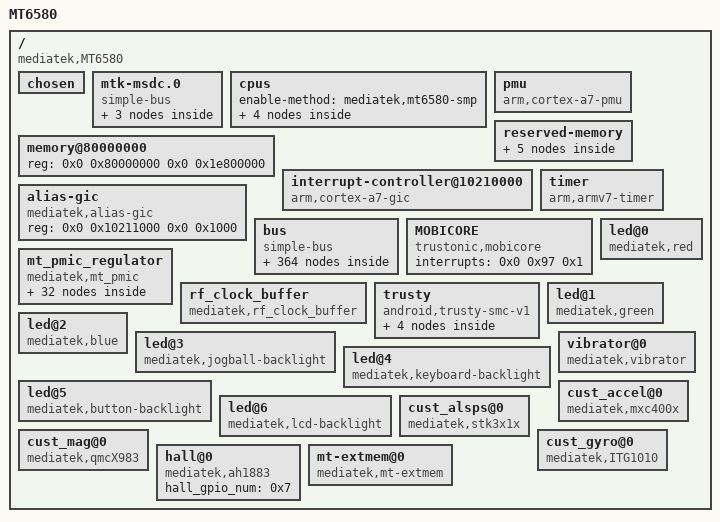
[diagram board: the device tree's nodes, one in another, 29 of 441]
/dts-v1/;

/ {
	model = "MT6580";
	compatible = "mediatek,MT6580";
	interrupt-parent = <0x1>;
	#address-cells = <0x2>;
	#size-cells = <0x2>;

	chosen {
		bootargs = "console=tty0 console=ttyMT0,921600n1 root=/dev/ram initrd=0x84000000,0x400000 loglevel=8";
		atag,videolfb-fb_base = <0x9e800000>;
		atag,videolfb-islcmfound = <0x1>;
		atag,videolfb-fps = <0x1770>;
		atag,videolfb-vramSize = <0x1800000>;
		atag,videolfb-lcmname = "nt35590_AUO";
	};

	mtk-msdc.0 {
		compatible = "simple-bus";
		#address-cells = <0x1>;
		#size-cells = <0x1>;
		ranges = <0x0 0x0 0x0 0xffffffff>;

		msdc0@11120000 {
			compatible = "mediatek,mt6580-mmc";
			reg = <0x11120000 0x10000 0x10001e84 0x2>;
			interrupts = <0x0 0x26 0x8>;
			status = "okay";
			clk_src = [07];
			bus-width = <0x8>;
			max-frequency = <0xc65d400>;
			cap-mmc-highspeed;
			msdc-sys-suspend;
			mmc-hs200-1_8v;
			non-removable;
			pinctl = <0x2>;
			register_setting = <0x3>;
			host_function = [00];
			bootable;
		};

		msdc1@11130000 {
			compatible = "mediatek,mt6580-mmc";
			reg = <0x11130000 0x10000 0x10001e84 0x2>;
			interrupts = <0x0 0x27 0x8>;
			cd-gpios = <0x4 0x14 0x0>;
			status = "okay";
			clk_src = [02];
			bus-width = <0x4>;
			max-frequency = <0xc65d400>;
			msdc-sys-suspend;
			cap-sd-highspeed;
			sd-uhs-sdr12;
			sd-uhs-sdr25;
			sd-uhs-sdr50;
			sd-uhs-sdr104;
			pinctrl-names = "default", "insert_cfg";
			pinctrl-0 = <0x5>;
			pinctrl-1 = <0x6>;
			pinctl = <0x7>;
			pinctl_sdr104 = <0x8>;
			pinctl_sdr50 = <0x9>;
			pinctl_ddr50 = <0xa>;
			register_setting = <0xb>;
			host_function = [01];
			cd_level = [00];
		};

		default {
			compatible = "mediatek,msdc1_ins-eint";
			interrupt-parent = <0xc>;
			interrupts = <0x14 0x8>;
			debounce = <0x14 0x0>;
			status = "okay";
		};
	};

	cpus {
		#address-cells = <0x1>;
		#size-cells = <0x0>;
		enable-method = "mediatek,mt6580-smp";

		cpu@0 {
			device_type = "cpu";
			compatible = "arm,cortex-a7";
			reg = <0x0>;
			clock-frequency = <0x6553f100>;
		};

		cpu@1 {
			device_type = "cpu";
			compatible = "arm,cortex-a7";
			reg = <0x1>;
			clock-frequency = <0x6553f100>;
		};

		cpu@2 {
			device_type = "cpu";
			compatible = "arm,cortex-a7";
			reg = <0x2>;
			clock-frequency = <0x6553f100>;
		};

		cpu@3 {
			device_type = "cpu";
			compatible = "arm,cortex-a7";
			reg = <0x3>;
			clock-frequency = <0x6553f100>;
		};
	};

	pmu {
		compatible = "arm,cortex-a7-pmu";
		interrupts = <0x0 0x4 0x8 0x0 0x5 0x8 0x0 0x6 0x8 0x0 0x7 0x8>;
	};

	memory@80000000 {
		device_type = "memory";
		reg = <0x0 0x80000000 0x0 0x1e800000>;
	};

	reserved-memory {
		#address-cells = <0x2>;
		#size-cells = <0x2>;
		ranges;

		consys-reserve-memory {
			compatible = "mediatek,consys-reserve-memory";
			no-map;
			size = <0x0 0x200000>;
			alignment = <0x0 0x200000>;
		};

		reserve-memory-ccci_md1 {
			compatible = "mediatek,reserve-memory-ccci_md1";
			no-map;
			size = <0x0 0x1800000>;
			alignment = <0x0 0x2000000>;
			alloc-ranges = <0x0 0x80000000 0x0 0x80000000>;
		};

		pstore-reserved-memory@83f10000 {
			compatible = "mediatek,pstore";
			reg = <0x0 0x83f10000 0x0 0xe0000>;
		};

		ram_console-reserved-memory@83f00000 {
			compatible = "mediatek,ram_console";
			reg = <0x0 0x83f00000 0x0 0x10000>;
		};

		minirdump-reserved-memory@83ff0000 {
			compatible = "mediatek, minirdump";
			reg = <0x0 0x83ff0000 0x0 0x10000>;
		};
	};

	interrupt-controller@10210000 {
		compatible = "arm,cortex-a7-gic";
		#interrupt-cells = <0x3>;
		#address-cells = <0x0>;
		interrupt-controller;
		reg = <0x0 0x10211000 0x0 0x1000 0x0 0x10212000 0x0 0x1000 0x0 0x10200100 0x0 0x1000>;
		interrupts = <0x1 0x9 0xf04>;
		linux,phandle = <0x1>;
		phandle = <0x1>;
	};

	alias-gic {
		compatible = "mediatek,alias-gic";
		reg = <0x0 0x10211000 0x0 0x1000>;
	};

	timer {
		compatible = "arm,armv7-timer";
		interrupts = <0x1 0xd 0x8 0x1 0xe 0x8 0x1 0xb 0x8 0x1 0xa 0x8>;
		clock-frequency = <0xc65d40>;
	};

	bus {
		compatible = "simple-bus";
		#address-cells = <0x1>;
		#size-cells = <0x1>;
		ranges = <0x0 0x0 0x0 0xffffffff>;

		chipid@08000000 {
			compatible = "mediatek,chipid";
			reg = <0x8000000 0x4 0x8000004 0x4 0x8000008 0x4 0x800000c 0x4>;
		};

		TOPCKGEN@0x10000000 {
			compatible = "mediatek,TOPCKGEN";
			reg = <0x10000000 0x1000>;
		};

		INFRACFG_AO@0x10001000 {
			compatible = "mediatek,INFRACFG_AO";
			reg = <0x10001000 0x1000>;
		};

		bat_meter {
			compatible = "mediatek,bat_meter";
			r_bat_sense = <0x4>;
			r_i_sense = <0x4>;
			r_charger_1 = <0x14a>;
			r_charger_2 = <0x27>;
			temperature_t0 = <0x6e>;
			temperature_t1 = <0x0>;
			temperature_t2 = <0x19>;
			temperature_t3 = <0x32>;
			temperature_t = <0xff>;
			fg_meter_resistance = <0x0>;
			q_max_pos_50 = <0x1359>;
			q_max_pos_25 = <0x13ec>;
			q_max_pos_0 = <0x13b2>;
			q_max_neg_10 = <0x11e3>;
			q_max_pos_50_h_current = <0x132f>;
			q_max_pos_25_h_current = <0x13ba>;
			q_max_pos_0_h_current = <0x1279>;
			q_max_neg_10_h_current = <0xdd0>;
			oam_d5 = <0x0>;
			change_tracking_point = <0x1>;
			cust_tracking_point = <0x0>;
			cust_r_sense = <0xc8>;
			cust_hw_cc = <0x0>;
			aging_tuning_value = <0x67>;
			cust_r_fg_offset = <0x0>;
			ocv_board_compesate = <0x0>;
			r_fg_board_base = <0x3e8>;
			r_fg_board_slope = <0x3e8>;
			car_tune_value = <0x59>;
			current_detect_r_fg = <0xa>;
			minerroroffset = <0x3e8>;
			fg_vbat_average_size = <0x12>;
			r_fg_value = <0xa>;
			cust_poweron_delta_capacity_tolrance = <0x1e>;
			cust_poweron_low_capacity_tolrance = <0x5>;
			cust_poweron_max_vbat_tolrance = <0x5a>;
			cust_poweron_delta_vbat_tolrance = <0x1e>;
			cust_poweron_delta_hw_sw_ocv_capacity_tolrance = <0xa>;
			fixed_tbat_25 = <0x0>;
			vbat_normal_wakeup = <0xe10>;
			vbat_low_power_wakeup = <0xdac>;
			normal_wakeup_period = <0x1518>;
			low_power_wakeup_period = <0x12c>;
			close_poweroff_wakeup_period = <0x1e>;
			rbat_pull_up_r = <0x4204>;
			rbat_pull_up_volt = <0x708>;
			batt_temperature_table_num = <0x13>;
			batt_temperature_table = <0xffffffec 0x10a8d 0xfffffff1 0xd192 0xfffffff6 0xa60a 0xfffffffb 0x8464 0x0 0x6a53 0x5 0x5605 0xa 0x4606 0xf 0x3952 0x14 0x2f31 0x19 0x2710 0x1e 0x207b 0x23 0x1b24 0x28 0x16ca 0x2d 0x1335 0x32 0x1041 0x37 0xdcf 0x3c 0xbc6 0x41 0xa28 0x46 0x8ca>;
			battery_profile_t0_num = <0x64>;
			battery_profile_t0 = <0x0 0x10e4 0x2 0x10c2 0x4 0x10a8 0x6 0x1091 0x8 0x107c 0x9 0x1068 0xb 0x1054 0xd 0x1041 0xf 0x102e 0x11 0x101b 0x13 0x1009 0x15 0xffa 0x17 0xfed 0x18 0xfd9 0x1a 0xfba 0x1c 0xf9a 0x1e 0xf83 0x20 0xf71 0x22 0xf63 0x24 0xf57 0x26 0xf4b 0x27 0xf3f 0x29 0xf32 0x2b 0xf26 0x2d 0xf1a 0x2f 0xf0f 0x31 0xf04 0x33 0xefb 0x35 0xef2 0x36 0xeeb 0x38 0xee3 0x3a 0xedd 0x3c 0xed7 0x3e 0xed1 0x40 0xecd 0x42 0xeca 0x44 0xec7 0x45 0xec5 0x47 0xec2 0x49 0xebf 0x4b 0xebc 0x4d 0xeb8 0x4f 0xeb4 0x51 0xeaf 0x53 0xea8 0x54 0xea1 0x56 0xe97 0x58 0xe8e 0x5a 0xe83 0x5c 0xe79 0x5e 0xe70 0x60 0xe68 0x61 0xe61 0x62 0xe5a 0x63 0xe50 0x64 0xdc8 0x64 0xdac 0x64 0xdac 0x64 0xdac 0x64 0xdac 0x64 0xdac 0x64 0xdac 0x64 0xdac 0x64 0xdac 0x64 0xdac 0x64 0xdac 0x64 0xdac 0x64 0xdac 0x64 0xdac 0x64 0xdac 0x64 0xdac 0x64 0xdac 0x64 0xdac 0x64 0xdac 0x64 0xdac 0x64 0xdac 0x64 0xdac 0x64 0xdac 0x64 0xdac 0x64 0xdac 0x64 0xdac 0x64 0xdac 0x64 0xdac 0x64 0xdac 0x64 0xdac 0x64 0xdac 0x64 0xdac 0x64 0xdac 0x64 0xdac 0x64 0xdac 0x64 0xdac 0x64 0xdac 0x64 0xdac 0x64 0xdac 0x64 0xdac 0x64 0xdac 0x64 0xdac 0x64 0xdac 0x64 0xdac 0x64 0xdac>;
			battery_profile_t1_num = <0x64>;
			battery_profile_t1 = <0x0 0x10e9 0x2 0x10cd 0x4 0x10b4 0x6 0x10a0 0x7 0x108c 0x9 0x1078 0xb 0x1065 0xd 0x1052 0xf 0x103f 0x11 0x102c 0x12 0x1018 0x14 0x1006 0x16 0xff5 0x18 0xfea 0x1a 0xfdc 0x1c 0xfbc 0x1e 0xf98 0x1f 0xf82 0x21 0xf72 0x23 0xf66 0x25 0xf5b 0x27 0xf4e 0x29 0xf3f 0x2b 0xf31 0x2c 0xf23 0x2e 0xf16 0x30 0xf0b 0x32 0xf01 0x34 0xef8 0x36 0xef0 0x37 0xee8 0x39 0xee2 0x3b 0xedb 0x3d 0xed5 0x3f 0xed0 0x41 0xecb 0x43 0xec7 0x44 0xec3 0x46 0xec0 0x48 0xebe 0x4a 0xeba 0x4c 0xeb7 0x4e 0xeb2 0x4f 0xead 0x51 0xea6 0x53 0xe9e 0x55 0xe93 0x57 0xe89 0x59 0xe7b 0x5b 0xe72 0x5c 0xe6e 0x5e 0xe69 0x60 0xe5c 0x62 0xe28 0x64 0xdbb 0x64 0xdac 0x64 0xdac 0x64 0xdac 0x64 0xdac 0x64 0xdac 0x64 0xdac 0x64 0xdac 0x64 0xdac 0x64 0xdac 0x64 0xdac 0x64 0xdac 0x64 0xdac 0x64 0xdac 0x64 0xdac 0x64 0xdac 0x64 0xdac 0x64 0xdac 0x64 0xdac 0x64 0xdac 0x64 0xdac 0x64 0xdac 0x64 0xdac 0x64 0xdac 0x64 0xdac 0x64 0xdac 0x64 0xdac 0x64 0xdac 0x64 0xdac 0x64 0xdac 0x64 0xdac 0x64 0xdac 0x64 0xdac 0x64 0xdac 0x64 0xdac 0x64 0xdac 0x64 0xdac 0x64 0xdac 0x64 0xdac 0x64 0xdac 0x64 0xdac 0x64 0xdac 0x64 0xdac 0x64 0xdac 0x64 0xdac 0x64 0xdac>;
			battery_profile_t2_num = <0x64>;
			battery_profile_t2 = <0x0 0x10f1 0x2 0x10d8 0x4 0x10c1 0x5 0x10ac 0x7 0x1097 0x9 0x1083 0xb 0x106e 0xd 0x105b 0xf 0x1047 0x10 0x1034 0x12 0x1021 0x14 0x100e 0x16 0xffb 0x18 0xfe9 0x19 0xfde 0x1b 0xfcf 0x1d 0xfb1 0x1f 0xf98 0x21 0xf8b 0x23 0xf84 0x24 0xf79 0x26 0xf6b 0x28 0xf5d 0x2a 0xf4c 0x2c 0xf37 0x2d 0xf24 0x2f 0xf16 0x31 0xf0a 0x33 0xf00 0x35 0xef7 0x37 0xeef 0x38 0xee8 0x3a 0xee1 0x3c 0xeda 0x3e 0xed5 0x40 0xecf 0x41 0xeca 0x43 0xec6 0x45 0xec1 0x47 0xebc 0x49 0xeb5 0x4b 0xead 0x4c 0xea8 0x4e 0xea1 0x50 0xe9b 0x52 0xe96 0x54 0xe8e 0x55 0xe83 0x57 0xe79 0x59 0xe6b 0x5b 0xe64 0x5d 0xe62 0x5f 0xe61 0x60 0xe58 0x62 0xe1b 0x64 0xdac 0x64 0xdac 0x64 0xdac 0x64 0xdac 0x64 0xdac 0x64 0xdac 0x64 0xdac 0x64 0xdac 0x64 0xdac 0x64 0xdac 0x64 0xdac 0x64 0xdac 0x64 0xdac 0x64 0xdac 0x64 0xdac 0x64 0xdac 0x64 0xdac 0x64 0xdac 0x64 0xdac 0x64 0xdac 0x64 0xdac 0x64 0xdac 0x64 0xdac 0x64 0xdac 0x64 0xdac 0x64 0xdac 0x64 0xdac 0x64 0xdac 0x64 0xdac 0x64 0xdac 0x64 0xdac 0x64 0xdac 0x64 0xdac 0x64 0xdac 0x64 0xdac 0x64 0xdac 0x64 0xdac 0x64 0xdac 0x64 0xdac 0x64 0xdac 0x64 0xdac 0x64 0xdac 0x64 0xdac 0x64 0xdac 0x64 0xdac>;
			battery_profile_t3_num = <0x64>;
			battery_profile_t3 = <0x0 0x10d9 0x2 0x10c2 0x4 0x10ad 0x6 0x1098 0x8 0x1083 0x9 0x106f 0xb 0x105a 0xd 0x1046 0xf 0x1033 0x11 0x101f 0x13 0x100c 0x15 0xff9 0x17 0xfe7 0x19 0xfd5 0x1a 0xfc4 0x1c 0xfb3 0x1e 0xfa2 0x20 0xf93 0x22 0xf83 0x24 0xf73 0x26 0xf63 0x28 0xf50 0x29 0xf3c 0x2b 0xf2a 0x2d 0xf1c 0x2f 0xf11 0x31 0xf06 0x33 0xefd 0x35 0xef4 0x37 0xeec 0x39 0xee4 0x3a 0xedd 0x3c 0xed7 0x3e 0xed0 0x40 0xecb 0x42 0xec6 0x44 0xec0 0x46 0xeba 0x48 0xeae 0x4a 0xea4 0x4b 0xe9d 0x4d 0xe95 0x4f 0xe8e 0x51 0xe89 0x53 0xe81 0x55 0xe76 0x57 0xe6c 0x59 0xe5f 0x5b 0xe59 0x5c 0xe58 0x5e 0xe56 0x60 0xe4d 0x62 0xe15 0x64 0xdb2 0x64 0xdac 0x64 0xdac 0x64 0xdac 0x64 0xdac 0x64 0xdac 0x64 0xdac 0x64 0xdac 0x64 0xdac 0x64 0xdac 0x64 0xdac 0x64 0xdac 0x64 0xdac 0x64 0xdac 0x64 0xdac 0x64 0xdac 0x64 0xdac 0x64 0xdac 0x64 0xdac 0x64 0xdac 0x64 0xdac 0x64 0xdac 0x64 0xdac 0x64 0xdac 0x64 0xdac 0x64 0xdac 0x64 0xdac 0x64 0xdac 0x64 0xdac 0x64 0xdac 0x64 0xdac 0x64 0xdac 0x64 0xdac 0x64 0xdac 0x64 0xdac 0x64 0xdac 0x64 0xdac 0x64 0xdac 0x64 0xdac 0x64 0xdac 0x64 0xdac 0x64 0xdac 0x64 0xdac 0x64 0xdac 0x64 0xdac 0x64 0xdac 0x64 0xdac>;
			r_profile_t0_num = <0x64>;
			r_profile_t0 = <0x351 0x10e4 0x351 0x10c2 0x34b 0x10a8 0x344 0x1091 0x334 0x107c 0x32b 0x1068 0x31f 0x1054 0x315 0x1041 0x30c 0x102e 0x301 0x101b 0x2f7 0x1009 0x2f4 0xffa 0x2f5 0xfed 0x2ed 0xfd9 0x2d0 0xfba 0x2b2 0xf9a 0x2a5 0xf83 0x29f 0xf71 0x29c 0xf63 0x29c 0xf57 0x296 0xf4b 0x28d 0xf3f 0x28d 0xf32 0x287 0xf26 0x283 0xf1a 0x27e 0xf0f 0x27e 0xf04 0x27e 0xefb 0x27e 0xef2 0x27e 0xeeb 0x281 0xee3 0x283 0xedd 0x286 0xed7 0x289 0xed1 0x28e 0xecd 0x295 0xeca 0x29f 0xec7 0x2af 0xec5 0x2bb 0xec2 0x2cb 0xebf 0x2da 0xebc 0x2ea 0xeb8 0x303 0xeb4 0x31b 0xeaf 0x337 0xea8 0x352 0xea1 0x379 0xe97 0x3a2 0xe8e 0x3d4 0xe83 0x67 0xe79 0x6e 0xe70 0x77 0xe68 0x78 0xe61 0x76 0xe5a 0x74 0xe50 0x335 0xdc8 0x335 0xdac 0x335 0xdac 0x335 0xdac 0x335 0xdac 0x335 0xdac 0x335 0xdac 0x335 0xdac 0x335 0xdac 0x335 0xdac 0x335 0xdac 0x335 0xdac 0x335 0xdac 0x335 0xdac 0x335 0xdac 0x335 0xdac 0x335 0xdac 0x335 0xdac 0x335 0xdac 0x335 0xdac 0x335 0xdac 0x335 0xdac 0x335 0xdac 0x335 0xdac 0x335 0xdac 0x335 0xdac 0x335 0xdac 0x335 0xdac 0x335 0xdac 0x335 0xdac 0x335 0xdac 0x335 0xdac 0x335 0xdac 0x335 0xdac 0x335 0xdac 0x335 0xdac 0x335 0xdac 0x335 0xdac 0x335 0xdac 0x335 0xdac 0x335 0xdac 0x335 0xdac 0x335 0xdac 0x335 0xdac 0x335 0xdac>;
			r_profile_t1_num = <0x64>;
			r_profile_t1 = <0x198 0x10e9 0x198 0x10cd 0x193 0x10b4 0x18d 0x10a0 0x186 0x108c 0x17e 0x1078 0x178 0x1065 0x173 0x1052 0x170 0x103f 0x16d 0x102c 0x169 0x1018 0x167 0x1006 0x166 0xff5 0x16d 0xfea 0x173 0xfdc 0x164 0xfbc 0x153 0xf98 0x14d 0xf82 0x149 0xf72 0x148 0xf66 0x147 0xf5b 0x13f 0xf4e 0x138 0xf3f 0x130 0xf31 0x12b 0xf23 0x128 0xf16 0x127 0xf0b 0x125 0xf01 0x126 0xef8 0x127 0xef0 0x128 0xee8 0x129 0xee2 0x12b 0xedb 0x12d 0xed5 0x12e 0xed0 0x130 0xecb 0x133 0xec7 0x137 0xec3 0x139 0xec0 0x138 0xebe 0x13c 0xeba 0x140 0xeb7 0x147 0xeb2 0x14c 0xead 0x154 0xea6 0x15c 0xe9e 0x166 0xe93 0x176 0xe89 0x188 0xe7b 0x19c 0xe72 0x1ba 0xe6e 0x1e6 0xe69 0x227 0xe5c 0x264 0xe28 0x2d7 0xdbb 0x2d7 0xdac 0x2d7 0xdac 0x2d7 0xdac 0x2d7 0xdac 0x2d7 0xdac 0x2d7 0xdac 0x2d7 0xdac 0x2d7 0xdac 0x2d7 0xdac 0x2d7 0xdac 0x2d7 0xdac 0x2d7 0xdac 0x2d7 0xdac 0x2d7 0xdac 0x2d7 0xdac 0x2d7 0xdac 0x2d7 0xdac 0x2d7 0xdac 0x2d7 0xdac 0x2d7 0xdac 0x2d7 0xdac 0x2d7 0xdac 0x2d7 0xdac 0x2d7 0xdac 0x2d7 0xdac 0x2d7 0xdac 0x2d7 0xdac 0x2d7 0xdac 0x2d7 0xdac 0x2d7 0xdac 0x2d7 0xdac 0x2d7 0xdac 0x2d7 0xdac 0x2d7 0xdac 0x2d7 0xdac 0x2d7 0xdac 0x2d7 0xdac 0x2d7 0xdac 0x2d7 0xdac 0x2d7 0xdac 0x2d7 0xdac 0x2d7 0xdac 0x2d7 0xdac 0x2d7 0xdac 0x2d7 0xdac>;
			r_profile_t2_num = <0x64>;
			r_profile_t2 = <0x7c 0x10f1 0x7c 0x10d8 0x7d 0x10c1 0x7b 0x10ac 0x7a 0x1097 0x7a 0x1083 0x7a 0x106e 0x7a 0x105b 0x79 0x1047 0x7b 0x1034 0x7d 0x1021 0x7c 0x100e 0x7c 0xffb 0x7c 0xfe9 0x85 0xfde 0x84 0xfcf 0x7d 0xfb1 0x7e 0xf98 0x80 0xf8b 0x88 0xf84 0x89 0xf79 0x8b 0xf6b 0x8d 0xf5d 0x8a 0xf4c 0x81 0xf37 0x7a 0xf24 0x77 0xf16 0x75 0xf0a 0x74 0xf00 0x74 0xef7 0x74 0xeef 0x75 0xee8 0x74 0xee1 0x73 0xeda 0x74 0xed5 0x74 0xecf 0x75 0xeca 0x76 0xec6 0x77 0xec1 0x77 0xebc 0x74 0xeb5 0x71 0xead 0x74 0xea8 0x74 0xea1 0x74 0xe9b 0x77 0xe96 0x76 0xe8e 0x76 0xe83 0x77 0xe79 0x77 0xe6b 0x74 0xe64 0x78 0xe62 0x81 0xe61 0x8c 0xe58 0x87 0xe1b 0x91 0xdac 0x91 0xdac 0x91 0xdac 0x91 0xdac 0x91 0xdac 0x91 0xdac 0x91 0xdac 0x91 0xdac 0x91 0xdac 0x91 0xdac 0x91 0xdac 0x91 0xdac 0x91 0xdac 0x91 0xdac 0x91 0xdac 0x91 0xdac 0x91 0xdac 0x91 0xdac 0x91 0xdac 0x91 0xdac 0x91 0xdac 0x91 0xdac 0x91 0xdac 0x91 0xdac 0x91 0xdac 0x91 0xdac 0x91 0xdac 0x91 0xdac 0x91 0xdac 0x91 0xdac 0x91 0xdac 0x91 0xdac 0x91 0xdac 0x91 0xdac 0x91 0xdac 0x91 0xdac 0x91 0xdac 0x91 0xdac 0x91 0xdac 0x91 0xdac 0x91 0xdac 0x91 0xdac 0x91 0xdac 0x91 0xdac 0x91 0xdac>;
			r_profile_t3_num = <0x64>;
			r_profile_t3 = <0x66 0x10d9 0x66 0x10c2 0x66 0x10ad 0x67 0x1098 0x67 0x1083 0x67 0x106f 0x66 0x105a 0x67 0x1046 0x67 0x1033 0x68 0x101f 0x68 0x100c 0x68 0xff9 0x69 0xfe7 0x6a 0xfd5 0x6c 0xfc4 0x6c 0xfb3 0x6d 0xfa2 0x70 0xf93 0x71 0xf83 0x73 0xf73 0x76 0xf63 0x74 0xf50 0x6d 0xf3c 0x69 0xf2a 0x67 0xf1c 0x68 0xf11 0x67 0xf06 0x67 0xefd 0x67 0xef4 0x66 0xeec 0x67 0xee4 0x68 0xedd 0x68 0xed7 0x69 0xed0 0x6a 0xecb 0x6c 0xec6 0x6d 0xec0 0x6d 0xeba 0x67 0xeae 0x68 0xea4 0x69 0xe9d 0x68 0xe95 0x67 0xe8e 0x6a 0xe89 0x6b 0xe81 0x69 0xe76 0x6b 0xe6c 0x67 0xe5f 0x66 0xe59 0x6d 0xe58 0x76 0xe56 0x7e 0xe4d 0x72 0xe15 0x77 0xdb2 0x89 0xdac 0x89 0xdac 0x89 0xdac 0x89 0xdac 0x89 0xdac 0x89 0xdac 0x89 0xdac 0x89 0xdac 0x89 0xdac 0x89 0xdac 0x89 0xdac 0x89 0xdac 0x89 0xdac 0x89 0xdac 0x89 0xdac 0x89 0xdac 0x89 0xdac 0x89 0xdac 0x89 0xdac 0x89 0xdac 0x89 0xdac 0x89 0xdac 0x89 0xdac 0x89 0xdac 0x89 0xdac 0x89 0xdac 0x89 0xdac 0x89 0xdac 0x89 0xdac 0x89 0xdac 0x89 0xdac 0x89 0xdac 0x89 0xdac 0x89 0xdac 0x89 0xdac 0x89 0xdac 0x89 0xdac 0x89 0xdac 0x89 0xdac 0x89 0xdac 0x89 0xdac 0x89 0xdac 0x89 0xdac 0x89 0xdac 0x89 0xdac 0x89 0xdac>;
		};

		bat_notify {
			compatible = "mediatek,bat_notify";
		};

		bat_comm {
			compatible = "mediatek,battery";
			stop_charging_in_takling = <0x1>;
			talking_recharge_voltage = <0xed8>;
			talking_sync_time = <0x3c>;
			mtk_temperature_recharge_support = <0x1>;
			max_charge_temperature = <0x46>;
			max_charge_temperature_minus_x_degree = <0x41>;
			min_charge_temperature = <0x0>;
			min_charge_temperature_plus_x_degree = <0x6>;
			err_charge_temperature = <0xff>;
			v_pre2cc_thres = <0xd48>;
			v_cc2topoff_thres = <0x1040>;
			recharging_voltage = <0x107c>;
			charging_full_current = <0x64>;
			config_usb_if = <0x0>;
			usb_charger_current_suspend = <0x0>;
			usb_charger_current_unconfigured = <0x1b58>;
			usb_charger_current_configured = <0xc350>;
			usb_charger_current = <0xc350>;
			ac_charger_current = <0x186a0>;
			non_std_ac_charger_current = <0x186a0>;
			charging_host_charger_current = <0xfde8>;
			apple_0_5a_charger_current = <0xc350>;
			apple_1_0a_charger_current = <0xfde8>;
			apple_2_1a_charger_current = <0x13880>;
			bat_low_temp_protect_enable = <0x0>;
			v_charger_enable = <0x0>;
			v_charger_max = <0x1964>;
			v_charger_min = <0x1130>;
			onehundred_percent_tracking_time = <0xa>;
			npercent_tracking_time = <0x14>;
			sync_to_real_tracking_time = <0x3c>;
			v_0percent_tracking = <0xdde>;
			high_battery_voltage_support = <0x1>;
		};

		keypad@10002000 {
			compatible = "mediatek,mt6580-keypad";
			reg = <0x10002000 0x1000>;
			interrupts = <0x0 0x6d 0x2>;
			mediatek,kpd-key-debounce = <0x400>;
			mediatek,kpd-sw-pwrkey = <0x74>;
			mediatek,kpd-hw-pwrkey = <0x8>;
			mediatek,kpd-sw-rstkey = <0x73>;
			mediatek,kpd-hw-rstkey = <0x11>;
			mediatek,kpd-use-extend-type = <0x0>;
			mediatek,kpd-hw-map-num = <0x48>;
			mediatek,kpd-hw-init-map = <0x72 0x0 0x0 0x0 0x0 0x0 0x0 0x0 0x0 0x0 0x66 0x0 0x0 0x0 0x0 0x0 0x0 0x0 0x0 0x0 0x0 0x0 0x0 0x0 0x0 0x0 0x0 0x0 0x0 0x0 0x0 0x0 0x0 0x0 0x0 0x0 0x0 0x0 0x0 0x0 0x0 0x0 0x0 0x0 0x0 0x0 0x0 0x0 0x0 0x0 0x0 0x0 0x0 0x0 0x0 0x0 0x0 0x0 0x0 0x0 0x0 0x0 0x0 0x0 0x0 0x0 0x0 0x0 0x0 0x0 0x0 0x0>;
			mediatek,kpd-pwrkey-eint-gpio = <0x0>;
			mediatek,kpd-pwkey-gpio-din = <0x0>;
			mediatek,kpd-hw-dl-key0 = <0x11>;
			mediatek,kpd-hw-dl-key1 = <0x0>;
			mediatek,kpd-hw-dl-key2 = <0x8>;
			mediatek,kpd-hw-recovery-key = <0x11>;
			mediatek,kpd-hw-factory-key = <0x0>;
			status = "okay";
		};

		PERICFG@0x10003000 {
			compatible = "mediatek,PERICFG";
			reg = <0x10003000 0x1000>;
		};

		RESERVED@0x10004000 {
			compatible = "mediatek,RESERVED";
			reg = <0x10004000 0x1000>;
		};

		gpio {
			compatible = "mediatek,gpio_usage_mapping";
			GPIO_SIM1_HOT_PLUG = <0x9>;
			GPIO_SIM1_SCLK = <0x16>;
			GPIO_SIM1_SIO = <0x17>;
			GPIO_SIM2_SIO = <0x18>;
			GPIO_SIM2_SCLK = <0x19>;
		};

		gpio@0x10005000 {
			compatible = "mediatek,gpio";
			reg = <0x10005000 0x1000>;
		};

		SLEEP@0x10006000 {
			compatible = "mediatek,SLEEP";
			reg = <0x10006000 0x1000>;
			interrupts = <0x0 0x58 0x8 0x0 0x59 0x8 0x0 0x5a 0x8 0x0 0x5b 0x8>;
		};

		TOPRGU@0x10007000 {
			compatible = "mediatek,TOPRGU";
			reg = <0x10007000 0x1000>;
			interrupts = <0x0 0x9d 0x2>;
		};

		APXGPT@0x10008000 {
			compatible = "mediatek,APXGPT";
			reg = <0x10008000 0x1000>;
			interrupts = <0x0 0x5c 0x8>;
			clock-frequency = <0xc65d40>;
		};

		EFUSEC@0x10009000 {
			compatible = "mediatek,EFUSEC";
			reg = <0x10009000 0x1000>;
		};

		hacc@0x1000A000 {
			compatible = "mediatek,hacc";
			reg = <0x1000a000 0x1000>;
			interrupts = <0x0 0x6e 0x0>;
		};

		cpu_dbgapb@10170000 {
			compatible = "mediatek,hw_dbg";
			num = <0x4>;
			reg = <0x10170000 0x2000 0x10172000 0x2000 0x10174000 0x2000 0x10176000 0x2000>;
		};

		eintc@1000b000 {
			compatible = "mediatek,mt-eic";
			reg = <0x1000b000 0x1000>;
			interrupts = <0x0 0x5e 0x4>;
			#interrupt-cells = <0x2>;
			interrupt-controller;
			mediatek,max_eint_num = <0x1a>;
			mediatek,mapping_table_entry = <0x53>;
			mediatek,mapping_table = <0x0 0x0 0x1 0x1 0x2 0x2 0x3 0x3 0x4 0x4 0x5 0x5 0x6 0x6 0x7 0x7 0x8 0x8 0x9 0x9 0xa 0xa 0xb 0xb 0xc 0xc 0xd 0xd 0xe 0xe 0xf 0xf 0x10 0x0 0x11 0x1 0x12 0x2 0x13 0x3 0x14 0x4 0x15 0x5 0x16 0x6 0x17 0x7 0x18 0x8 0x19 0x9 0x1a 0xa 0x1b 0xb 0x1c 0xc 0x1d 0xd 0x1e 0xe 0x1f 0xf 0x20 0x0 0x21 0x1 0x22 0x2 0x23 0x3 0x24 0x4 0x25 0x5 0x26 0x6 0x27 0x7 0x28 0x8 0x29 0x9 0x2a 0xa 0x2b 0xb 0x2c 0xc 0x2d 0xd 0x2e 0xe 0x2f 0xf 0x30 0x0 0x31 0x1 0x32 0x2 0x33 0x3 0x34 0x3 0x35 0x4 0x36 0x5 0x37 0x6 0x38 0x7 0x39 0x8 0x3a 0xa 0x3b 0xb 0x3c 0xc 0x3d 0xd 0x3e 0xe 0x3f 0xf 0x40 0x0 0x41 0x1 0x42 0x2 0x43 0x3 0x44 0x10 0x45 0x4 0x46 0x5 0x47 0x6 0x48 0x7 0x49 0x8 0x4a 0x9 0x4b 0xa 0x4c 0xb 0x4d 0xc 0x4e 0xd 0x51 0x0 0x52 0x1 0x53 0x2 0x54 0x3>;
			mediatek,builtin_entry = <0xb>;
			mediatek,builtin_mapping = <0x0 0x3 0x14 0x1 0x3 0x12 0x7 0x4 0x14 0x8 0x4 0x12 0x9 0x3 0x14 0xa 0x3 0x12 0x18 0x5 0x14 0x19 0x5 0x12 0x4d 0x2 0x14 0x4e 0x2 0x12 0xd 0x1 0x11>;
			linux,phandle = <0xc>;
			phandle = <0xc>;

			MD1_SIM1_HOT_PLUG_EINT@0 {
				compatible = "mediatek,MD1_SIM1_HOT_PLUG_EINT-eint";
				interrupts = <0x0 0x4>;
				debounce = <0x0 0x2710>;
				dedicated = <0x0 0x1>;
				src_pin = <0x0 0x820c078>;
				sockettype = <0x0 0x0>;
				status = "okay";
			};

			pmic@13 {
				compatible = "mediatek, pmic-eint";
				interrupt-parent = <0xc>;
				interrupts = <0xd 0x4>;
				debounce = <0xd 0x3e8>;
			};
		};

		ap_ccif0@1000C000 {
			compatible = "mediatek,ap_ccif0";
			reg = <0x1000c000 0x1000 0x1000d000 0x1000>;
			interrupts = <0x0 0x5d 0x8 0x0 0x98 0x2>;
			mediatek,ccif_capability = <0x2>;
			mediatek,md_smem_size = <0x200000>;
		};

		MCUSYS_CFGREG@0x1020000 {
			compatible = "mediatek,MCUSYS_CFGREG_BASE";
			reg = <0x1020000 0x200>;
		};

		mcucfg@10200000 {
			compatible = "mediatek,mt6580-mcucfg";
			reg = <0x10200000 0x200>;
		};

		AES@0x1000E000 {
			compatible = "mediatek,AES";
			reg = <0x1000e000 0x1000>;
		};

		PWRAP@0x1000F000 {
			compatible = "mediatek,PWRAP";
			reg = <0x1000f000 0x1000>;
			interrupts = <0x0 0x6c 0x0>;
		};

		DEVAPC_AO@0x10010000 {
			compatible = "mediatek,DEVAPC_AO";
			reg = <0x10010000 0x1000>;
		};

		MIPI_CONFG@0x10011000 {
			compatible = "mediatek,MIPI_CONFG";
			reg = <0x10011000 0x1000>;
		};

		INFRA_MBIST@0x10012000 {
			compatible = "mediatek,INFRA_MBIST";
			reg = <0x10012000 0x1000>;
		};

		RESERVED@0x10013000 {
			compatible = "mediatek,RESERVED";
			reg = <0x10013000 0x1000>;
		};

		IOCFG_T@0x10014000 {
			compatible = "mediatek,IOCFG_T";
			reg = <0x10014000 0x1000>;
		};

		IOCFG_B@0x10015000 {
			compatible = "mediatek,IOCFG_B";
			reg = <0x10015000 0x1000>;
		};

		IOCFG_L@0x10016000 {
			compatible = "mediatek,IOCFG_L";
			reg = <0x10016000 0x1000>;
		};

		IOCFG_R@0x10017000 {
			compatible = "mediatek,IOCFG_R";
			reg = <0x10017000 0x1000>;
		};

		APMIXED@0x10018000 {
			compatible = "mediatek,APMIXED";
			reg = <0x10018000 0x1000>;
		};

		MCUCFG@0x10200000 {
			compatible = "mediatek,MCUCFG";
			reg = <0x10200000 0x1000>;
		};

		INFRACFG@0x10201000 {
			compatible = "mediatek,INFRACFG";
			reg = <0x10201000 0x1000>;
		};

		sys_cirq@10202000 {
			compatible = "mediatek,mt6580-sys_cirq", "mediatek,mt6735-sys_cirq";
			reg = <0x10202000 0x1000>;
			interrupts = <0x0 0x9e 0x8>;
			mediatek,cirq_num = <0x7e>;
			mediatek,spi_start_offset = <0x20>;
		};

		m4u@10203000 {
			cell-index = <0x0>;
			compatible = "mediatek,m4u";
			reg = <0x10203000 0x1000>;
			interrupts = <0x0 0x51 0x8>;
		};

		DEVAPC@0x10204000 {
			compatible = "mediatek,DEVAPC";
			reg = <0x10204000 0x1000>;
			interrupts = <0x0 0x4a 0x8>;
		};

		EMI@0x10205000 {
			compatible = "mediatek,EMI";
			reg = <0x10205000 0x1000>;
			interrupts = <0x0 0x4c 0x4>;
		};

		DRAMC_NAO@0x10206000 {
			compatible = "mediatek,DRAMC_NAO";
			reg = <0x10206000 0x1000>;
		};

		DRAMC0@0x10207000 {
			compatible = "mediatek,DRAMC0";
			reg = <0x10207000 0x1000>;
		};

		DDRPHY@0x10208000 {
			compatible = "mediatek,DDRPHY";
			reg = <0x10208000 0x1000>;
		};

		SRAMROM@0x10209000 {
			compatible = "mediatek,SRAMROM";
			reg = <0x10209000 0x1000>;
		};

		gce@1020a000 {
			compatible = "mediatek,gce";
			reg = <0x1020a000 0x1000>;
			interrupts = <0x0 0x55 0x8 0x0 0x56 0x8>;
			disp_mutex_reg = <0x14015000 0x1000>;
			g3d_config_base = <0x13000000 0x0 0xffff0000>;
			mmsys_config_base = <0x14000000 0x1 0xffff0000>;
			disp_dither_base = <0x14010000 0x2 0xffff0000>;
			mm_na_base = <0x14020000 0x3 0xffff0000>;
			imgsys_base = <0x15000000 0x4 0xffff0000>;
			vdec_gcon_base = <0x16000000 0x5 0xffff0000>;
			venc_gcon_base = <0x17000000 0x6 0xffff0000>;
			conn_peri_base = <0x18000000 0x7 0xffff0000>;
			topckgen_base = <0x10000000 0x8 0xffff0000>;
			kp_base = <0x10010000 0x9 0xffff0000>;
			scp_sram_base = <0x10020000 0xa 0xffff0000>;
			infra_na3_base = <0x10030000 0xb 0xffff0000>;
			infra_na4_base = <0x10040000 0xc 0xffff0000>;
			scp_base = <0x10050000 0xd 0xffff0000>;
			mcucfg_base = <0x10200000 0xe 0xffff0000>;
			gcpu_base = <0x10210000 0xf 0xffff0000>;
			usb0_base = <0x11200000 0x10 0xffff0000>;
			usb_sif_base = <0x11210000 0x11 0xffff0000>;
			audio_base = <0x11220000 0x12 0xffff0000>;
			msdc0_base = <0x11230000 0x13 0xffff0000>;
			msdc1_base = <0x11240000 0x14 0xffff0000>;
			msdc2_base = <0x11250000 0x15 0xffff0000>;
			msdc3_base = <0x11260000 0x16 0xffff0000>;
			pwm_sw_base = <0x1100f000 0x63 0xfffff000>;
			mdp_rdma0_sof = <0x0>;
			mdp_rsz0_sof = <0x1>;
			mdp_rsz1_sof = <0x2>;
			mdp_tdshp_sof = <0x3>;
			mdp_wdma_sof = <0x4>;
			mdp_wrot_sof = <0x5>;
			disp_ovl0_sof = <0x6>;
			disp_rdma0_sof = <0x8>;
			disp_wdma0_sof = <0xa>;
			disp_color_sof = <0xc>;
			disp_aal_sof = <0xd>;
			disp_gamma_sof = <0xe>;
			disp_dither_sof = <0xf>;
			disp_pwm0_sof = <0x11>;
			mdp_rdma0_frame_done = <0x12>;
			mdp_rsz0_frame_done = <0x13>;
			mdp_rsz1_frame_done = <0x14>;
			mdp_tdshp_frame_done = <0x15>;
			mdp_wdma_frame_done = <0x16>;
			mdp_wrot_write_frame_done = <0x17>;
			mdp_wrot_read_frame_done = <0x18>;
			disp_ovl0_frame_done = <0x19>;
			disp_rdma0_frame_done = <0x1b>;
			disp_wdma0_frame_done = <0x1d>;
			disp_color_frame_done = <0x1f>;
			disp_aal_frame_done = <0x20>;
			disp_gamma_frame_done = <0x21>;
			disp_dither_frame_done = <0x22>;
			disp_dsi0_frame_done = <0x25>;
			stream_done_0 = <0x26>;
			stream_done_1 = <0x27>;
			stream_done_2 = <0x28>;
			stream_done_3 = <0x29>;
			stream_done_4 = <0x2a>;
			stream_done_5 = <0x2b>;
			stream_done_6 = <0x2c>;
			stream_done_7 = <0x2d>;
			stream_done_8 = <0x2e>;
			stream_done_9 = <0x2f>;
			buf_underrun_event_0 = <0x30>;
			dsi0_te_event = <0x32>;
			isp_frame_done_p2_1 = <0x42>;
			isp_frame_done_p2_0 = <0x43>;
			seninf_cam0_fifo_full = <0x49>;
			apxgpt2_count = <0x10008028>;
		};

		bus_dbg@1020b000 {
			compatible = "mediatek,bus_dbg-v2";
			reg = <0x1020b000 0x1000>;
			interrupts = <0x0 0x49 0x8>;
			two_stage_timeout = <0x1>;
		};

		TRNG@0x1020C000 {
			compatible = "mediatek,TRNG";
			reg = <0x1020c000 0x1000>;
			interrupts = <0x0 0x57 0x8>;
		};

		MCUCFG_BIU@0x1020D000 {
			compatible = "mediatek,MCUCFG_BIU";
			reg = <0x1020d000 0x1000>;
		};

		DBGSYS_DEM@0x1011A000 {
			compatible = "mediatek,DBGSYS_DEM";
			reg = <0x1011a000 0x1000>;
		};

		DBGSYS_CTI@0x10112000 {
			compatible = "mediatek,DBGSYS_CTI";
			reg = <0x10112000 0x1000>;
		};

		DBGSYS_DAPROM@0x10110000 {
			compatible = "mediatek,DBGSYS_DAPROM";
			reg = <0x10110000 0x1000>;
		};

		DBGSYS_CPU@0x10160000 {
			compatible = "mediatek,DBGSYS_CPU";
			reg = <0x10160000 0x20000>;
		};

		DBGSYS_MDSYS@0x10120000 {
			compatible = "mediatek,DBGSYS_MDSYS";
			reg = <0x10120000 0x10000>;
		};

		dma@0x11000000 {
			compatible = "mediatek,ap_dma";
			reg = <0x11000000 0x1000>;
			interrupts = <0x0 0x30 0x8>;
		};

		NFI@0x11001000 {
			compatible = "mediatek,NFI";
			reg = <0x11001000 0x1000>;
			interrupts = <0x0 0x2f 0x8>;
		};

		NFIECC@0x11002000 {
			compatible = "mediatek,NFIECC";
			reg = <0x11002000 0x1000>;
			interrupts = <0x0 0x2e 0x8>;
		};

		adc_hw@11003000 {
			compatible = "mediatek,mt6735-auxadc";
			reg = <0x11003000 0x1000>;
			interrupts = <0x0 0x23 0x2>;

			adc_channel@ {
				compatible = "mediatek,adc_channel";
				mediatek,temperature0 = <0x0>;
				mediatek,temperature1 = <0x1>;
				status = "okay";
			};
		};

		FHCTL@0x11004000 {
			compatible = "mediatek,FHCTL";
			reg = <0x11004000 0x1000>;
		};

		AP_UART0@0x11005000 {
			cell-index = <0x0>;
			compatible = "mediatek,AP_UART0";
			reg = <0x11005000 0x1000>;
			interrupts = <0x0 0x2c 0x8>;
		};

		AP_UART1@0x11006000 {
			cell-index = <0x1>;
			compatible = "mediatek,AP_UART1";
			reg = <0x11006000 0x1000>;
			interrupts = <0x0 0x2d 0x8>;
		};

		AP_DMA_UART0_TX@0x11000480 {
			compatible = "mediatek,AP_DMA_UART0_TX";
			reg = <0x11000480 0x80>;
			interrupts = <0x0 0x38 0x8>;
		};

		AP_DMA_UART0_RX@0x11000500 {
			compatible = "mediatek,AP_DMA_UART0_RX";
			reg = <0x11000500 0x80>;
			interrupts = <0x0 0x39 0x8>;
		};

		AP_DMA_UART1_TX@0x11000580 {
			compatible = "mediatek,AP_DMA_UART1_TX";
			reg = <0x11000580 0x80>;
			interrupts = <0x0 0x3a 0x8>;
		};

		AP_DMA_UART1_RX@0x11000600 {
			compatible = "mediatek,AP_DMA_UART1_RX";
			reg = <0x11000600 0x80>;
			interrupts = <0x0 0x3b 0x8>;
		};

		PWM@0x11008000 {
			compatible = "mediatek,PWM";
			reg = <0x11008000 0x1000>;
			interrupts = <0x0 0x24 0x8>;
		};

		syscfg_pctl_a@0x10005000 {
			compatible = "mediatek,mt6580-pctl-a-syscfg", "syscon";
			reg = <0x10211000 0x1000>;
			linux,phandle = <0xd>;
			phandle = <0xd>;
		};

		pinctrl@0x10005000 {
			compatible = "mediatek,mt6580-pinctrl";
			reg = <0x10005000 0x1000>;
			mediatek,pctl-regmap = <0xd>;
			pins-are-numbered;
			gpio-controller;
			#gpio-cells = <0x2>;
			linux,phandle = <0x4>;
			phandle = <0x4>;

			mmc0@default {
				linux,phandle = <0x2>;
				phandle = <0x2>;

				pins_cmd {
					drive-strength = [02];
				};

				pins_dat {
					drive-strength = [02];
				};

				pins_clk {
					drive-strength = [02];
				};

				pins_rst {
					drive-strength = [02];
				};

				pins_ds {
					drive-strength = [02];
				};
			};

			mmc0@register_default {
				dat0rddly = [00];
				dat1rddly = [00];
				dat2rddly = [00];
				dat3rddly = [00];
				dat4rddly = [00];
				dat5rddly = [00];
				dat6rddly = [00];
				dat7rddly = [00];
				datwrddly = [00];
				cmdrrddly = [00];
				cmdrddly = [00];
				cmd_edge = [01];
				rdata_edge = [01];
				wdata_edge = [01];
				ett-hs200-cells = <0xc>;
				ett-hs200-default = <0xb0 0x380 0x0 0xb0 0x7c00 0x0 0xb4 0x38 0x1 0x4 0x2 0x1 0xf0 0x1f0000 0x0 0xf0 0x7c00000 0x0 0xb4 0x7 0x1 0xf0 0x1f 0x0 0x4 0x100 0x1 0xf8 0x1f000000 0x0 0xf0 0x1f00 0x0 0xb0 0x8 0x1>;
				linux,phandle = <0x3>;
				phandle = <0x3>;
			};

			mmc1_ins_default {
				linux,phandle = <0x5>;
				phandle = <0x5>;
			};

			mmc1_ins_cfg {
				linux,phandle = <0x6>;
				phandle = <0x6>;

				pins_insert {
					pins = <0x1406>;
					input-schmitt-enable = <0x1>;
					slew-rate = <0x0>;
					bias-pull-up = <0x0>;
				};
			};

			mmc1@default {
				linux,phandle = <0x7>;
				phandle = <0x7>;

				pins_cmd {
					drive-strength = [03];
				};

				pins_dat {
					drive-strength = [03];
				};

				pins_clk {
					drive-strength = [03];
				};
			};

			mmc1@sdr104 {
				linux,phandle = <0x8>;
				phandle = <0x8>;

				pins_cmd {
					drive-strength = [02];
				};

				pins_dat {
					drive-strength = [02];
				};

				pins_clk {
					drive-strength = [03];
				};
			};

			mmc1@sdr50 {
				linux,phandle = <0x9>;
				phandle = <0x9>;

				pins_cmd {
					drive-strength = [02];
				};

				pins_dat {
					drive-strength = [02];
				};

				pins_clk {
					drive-strength = [03];
				};
			};

			mmc1@ddr50 {
				linux,phandle = <0xa>;
				phandle = <0xa>;

				pins_cmd {
					drive-strength = [02];
				};

				pins_dat {
					drive-strength = [02];
				};

				pins_clk {
					drive-strength = [03];
				};
			};

			mmc1@register_default {
				dat0rddly = [00];
				dat1rddly = [00];
				dat2rddly = [00];
				dat3rddly = [00];
				datwrddly = [00];
				cmdrrddly = [00];
				cmdrddly = [00];
				cmd_edge = [01];
				rdata_edge = [01];
				wdata_edge = [01];
				linux,phandle = <0xb>;
				phandle = <0xb>;
			};

			alspspincfg {
				linux,phandle = <0x4b>;
				phandle = <0x4b>;

				pins_cmd_dat {
					pins = <0x606>;
					slew-rate = <0x0>;
					bias-pull-up = <0x0>;
				};
			};

			alspsdefaultcfg {
				linux,phandle = <0x4a>;
				phandle = <0x4a>;
			};

			gyropincfg {
				linux,phandle = <0x4d>;
				phandle = <0x4d>;

				pins_cmd_dat {
					pins = <0x100>;
					slew-rate = <0x0>;
					bias-pull-down = <0x0>;
				};
			};

			gyrodefaultcfg {
				linux,phandle = <0x4c>;
				phandle = <0x4c>;
			};

			eint0default {
				linux,phandle = <0x15>;
				phandle = <0x15>;
			};

			eint@0 {
				linux,phandle = <0x16>;
				phandle = <0x16>;

				pins_cmd_dat {
					pins = <0x1006>;
					slew-rate = <0x0>;
					bias-disable;
				};
			};

			toucheint5default {
				linux,phandle = <0xf>;
				phandle = <0xf>;
			};

			toucheint@5 {
				linux,phandle = <0x10>;
				phandle = <0x10>;

				pins_cmd_dat {
					pins = <0x506>;
					slew-rate = <0x0>;
					bias-disable;
				};
			};

			eintoutput0 {
				linux,phandle = <0x11>;
				phandle = <0x11>;

				pins_cmd_dat {
					pins = <0x500>;
					slew-rate = <0x1>;
					output-low;
				};
			};

			eintoutput1 {
				linux,phandle = <0x12>;
				phandle = <0x12>;

				pins_cmd_dat {
					pins = <0x500>;
					slew-rate = <0x1>;
					output-high;
				};
			};

			rstoutput0 {
				linux,phandle = <0x13>;
				phandle = <0x13>;

				pins_cmd_dat {
					pins = <0x800>;
					slew-rate = <0x1>;
					output-low;
				};
			};

			rstoutput1 {
				linux,phandle = <0x14>;
				phandle = <0x14>;

				pins_cmd_dat {
					pins = <0x800>;
					slew-rate = <0x1>;
					output-high;
				};
			};

			audiodefault {
				linux,phandle = <0x2e>;
				phandle = <0x2e>;
			};

			pmicclkmode0 {
				linux,phandle = <0x2f>;
				phandle = <0x2f>;

				pins_cmd0_dat {
					pins = <0x1a00>;
				};

				pins_cmd1_dat {
					pins = <0x1c00>;
				};

				pins_cmd2_dat {
					pins = <0x1b00>;
				};
			};

			pmicclkmode1 {
				linux,phandle = <0x30>;
				phandle = <0x30>;

				pins_cmd0_dat {
					pins = <0x1a01>;
				};

				pins_cmd1_dat {
					pins = <0x1c01>;
				};

				pins_cmd2_dat {
					pins = <0x1b01>;
				};
			};

			extamp@0 {
				linux,phandle = <0x31>;
				phandle = <0x31>;

				pins_cmd_dat {
					pins = <0xe00>;
					slew-rate = <0x1>;
					output-low;
				};
			};

			extamp@1 {
				linux,phandle = <0x32>;
				phandle = <0x32>;

				pins_cmd_dat {
					pins = <0xe00>;
					slew-rate = <0x1>;
					output-high;
				};
			};

			mode_te_gpio {
				linux,phandle = <0x4e>;
				phandle = <0x4e>;

				pins_cmd_dat {
					pins = <0x4400>;
				};
			};

			mode_te_te {
				linux,phandle = <0x4f>;
				phandle = <0x4f>;

				pins_cmd_dat {
					pins = <0x4401>;
				};
			};

			lcm_rst_out0_gpio {
				linux,phandle = <0x50>;
				phandle = <0x50>;

				pins_cmd_dat {
					pins = <0x4601>;
					slew-rate = <0x1>;
					output-low;
				};
			};

			lcm_rst_out1_gpio {
				linux,phandle = <0x51>;
				phandle = <0x51>;

				pins_cmd_dat {
					pins = <0x4601>;
					slew-rate = <0x1>;
					output-high;
				};
			};

			pwm_test_pin_mux_gpio66 {
				linux,phandle = <0x52>;
				phandle = <0x52>;

				pins_cmd_dat {
					pins = <0x4201>;
					slew-rate = <0x1>;
				};
			};

			default {
				linux,phandle = <0x1b>;
				phandle = <0x1b>;
			};

			flash_mode@0 {
				linux,phandle = <0x28>;
				phandle = <0x28>;

				pins_cmd_dat {
					pins = <0xb00>;
					slew-rate = <0x1>;
					output-low;
				};
			};

			flash_mode@1 {
				linux,phandle = <0x29>;
				phandle = <0x29>;

				pins_cmd_dat {
					pins = <0xb00>;
					slew-rate = <0x1>;
					output-high;
				};
			};

			flash_en@0 {
				linux,phandle = <0x2a>;
				phandle = <0x2a>;

				pins_cmd_dat {
					pins = <0xf00>;
					slew-rate = <0x1>;
					output-low;
				};
			};

			flash_en@1 {
				linux,phandle = <0x2b>;
				phandle = <0x2b>;

				pins_cmd_dat {
					pins = <0xf00>;
					slew-rate = <0x1>;
					output-high;
				};
			};

			flash_1w@0 {
				linux,phandle = <0x2c>;
				phandle = <0x2c>;

				pins_cmd_dat {
					pins = <0x700>;
					slew-rate = <0x1>;
					output-low;
				};
			};

			flash_1w@1 {
				linux,phandle = <0x2d>;
				phandle = <0x2d>;

				pins_cmd_dat {
					pins = <0x700>;
					slew-rate = <0x1>;
					output-high;
				};
			};

			cam0@0 {
				linux,phandle = <0x38>;
				phandle = <0x38>;

				pins_cmd_dat {
					pins = <0x4900>;
					slew-rate = <0x1>;
					output-low;
				};
			};

			cam0@1 {
				linux,phandle = <0x39>;
				phandle = <0x39>;

				pins_cmd_dat {
					pins = <0x4900>;
					slew-rate = <0x1>;
					output-high;
				};
			};

			cam0@2 {
				linux,phandle = <0x3a>;
				phandle = <0x3a>;

				pins_cmd_dat {
					pins = <0x4700>;
					slew-rate = <0x1>;
					output-low;
				};
			};

			cam0@3 {
				linux,phandle = <0x3b>;
				phandle = <0x3b>;

				pins_cmd_dat {
					pins = <0x4700>;
					slew-rate = <0x1>;
					output-high;
				};
			};

			cam1@0 {
				linux,phandle = <0x3c>;
				phandle = <0x3c>;

				pins_cmd_dat {
					pins = <0x4c00>;
					slew-rate = <0x1>;
					output-low;
				};
			};

			cam1@1 {
				linux,phandle = <0x3d>;
				phandle = <0x3d>;

				pins_cmd_dat {
					pins = <0x4c00>;
					slew-rate = <0x1>;
					output-high;
				};
			};

			cam1@2 {
				linux,phandle = <0x3e>;
				phandle = <0x3e>;

				pins_cmd_dat {
					pins = <0x4a00>;
					slew-rate = <0x1>;
					output-low;
				};
			};

			cam1@3 {
				linux,phandle = <0x3f>;
				phandle = <0x3f>;

				pins_cmd_dat {
					pins = <0x4a00>;
					slew-rate = <0x1>;
					output-high;
				};
			};

			cam@0 {
				linux,phandle = <0x40>;
				phandle = <0x40>;
			};

			cam@1 {
				linux,phandle = <0x41>;
				phandle = <0x41>;
			};

			camdefault {
				linux,phandle = <0x37>;
				phandle = <0x37>;
			};

			cam1serial@0 {
				linux,phandle = <0x42>;
				phandle = <0x42>;

				pins_cmd_dat {
					pins = <0x2302>;
				};

				pins_cmd_dat1 {
					pins = <0x2402>;
				};

				pins_cmd_dat2 {
					pins = <0x2502>;
				};

				pins_cmd_dat3 {
					pins = <0x2602>;
				};

				pins_cmd_dat4 {
					pins = <0x2702>;
				};
			};

			cam1mipi@0 {
				linux,phandle = <0x43>;
				phandle = <0x43>;

				pins_cmd_dat {
					pins = <0x2301>;
				};

				pins_cmd_dat1 {
					pins = <0x2401>;
				};

				pins_cmd_dat2 {
					pins = <0x2501>;
				};

				pins_cmd_dat3 {
					pins = <0x2601>;
				};

				pins_cmd_dat4 {
					pins = <0x2701>;
				};

				pins_cmd_dat5 {
					pins = <0x2801>;
				};
			};

			mclk1enable@0 {
				linux,phandle = <0x44>;
				phandle = <0x44>;

				pins_cmd_dat {
					pins = <0x4801>;
				};
			};

			mclk1disable@0 {
				linux,phandle = <0x45>;
				phandle = <0x45>;

				pins_cmd_dat {
					pins = <0x4800>;
				};
			};

			mclk2enable@0 {
				linux,phandle = <0x46>;
				phandle = <0x46>;

				pins_cmd_dat {
					pins = <0x4b01>;
				};
			};

			mclk2disable@0 {
				linux,phandle = <0x47>;
				phandle = <0x47>;

				pins_cmd_dat {
					pins = <0x4b00>;
				};
			};

			lens@0 {
				linux,phandle = <0x48>;
				phandle = <0x48>;

				pins_cmd_dat {
					pins = <0x1100>;
					slew-rate = <0x1>;
					output-low;
				};
			};

			lens@1 {
				linux,phandle = <0x49>;
				phandle = <0x49>;

				pins_cmd_dat {
					pins = <0x1100>;
					slew-rate = <0x1>;
					output-high;
				};
			};

			gpslna@0 {
				linux,phandle = <0x1c>;
				phandle = <0x1c>;

				pins_cmd_dat {
					pins = <0x400>;
					slew-rate = <0x0>;
					bias-disable;
					output-low;
				};
			};

			gpslna@1 {
				linux,phandle = <0x1d>;
				phandle = <0x1d>;

				pins_cmd_dat {
					pins = <0x400>;
					slew-rate = <0x1>;
					output-high;
				};
			};

			gpslna@2 {
				linux,phandle = <0x1e>;
				phandle = <0x1e>;

				pins_cmd_dat {
					pins = <0x400>;
					slew-rate = <0x1>;
					output-low;
				};
			};

			fingerprint_default {
				linux,phandle = <0x22>;
				phandle = <0x22>;
			};

			fingerprint_pin_irq {
				linux,phandle = <0x23>;
				phandle = <0x23>;

				pins_cmd_dat {
					pins = <0xc06>;
					slew-rate = <0x0>;
					bias-disable;
				};
			};

			fingerprint_reset_high {
				linux,phandle = <0x24>;
				phandle = <0x24>;

				pins_cmd_dat {
					pins = <0x1500>;
					slew-rate = <0x1>;
					output-high;
				};
			};

			fingerprint_reset_low {
				linux,phandle = <0x25>;
				phandle = <0x25>;

				pins_cmd_dat {
					pins = <0x1500>;
					slew-rate = <0x1>;
					output-low;
				};
			};

			eint@default {
				linux,phandle = <0x26>;
				phandle = <0x26>;
			};

			eint@7 {
				linux,phandle = <0x27>;
				phandle = <0x27>;

				pins_cmd_dat {
					pins = <0x706>;
					slew-rate = <0x0>;
					bias-disable;
				};
			};

			ledchrdefault {
				linux,phandle = <0x1f>;
				phandle = <0x1f>;
			};

			led_chr@0 {
				linux,phandle = <0x20>;
				phandle = <0x20>;

				pins_cmd_dat {
					pins = <0x1300>;
					slew-rate = <0x1>;
					output-low;
				};
			};

			led_chr@1 {
				linux,phandle = <0x21>;
				phandle = <0x21>;

				pins_cmd_dat {
					pins = <0x1300>;
					slew-rate = <0x1>;
					output-high;
				};
			};
		};

		i2c@11009000 {
			compatible = "mediatek,mt6580-i2c", "mediatek,i2c0";
			cell-index = <0x0>;
			reg = <0x11009000 0x1000>;
			interrupts = <0x0 0x28 0x8 0x0 0x32 0x8>;
			clock-div = <0xa>;
			#address-cells = <0x1>;
			#size-cells = <0x0>;

			camera_main@10 {
				compatible = "mediatek,camera_main";
				reg = <0x10>;
				status = "okay";
			};

			camera_main_af@0c {
				compatible = "mediatek,camera_main_af";
				reg = <0xc>;
				status = "okay";
			};

			camera_sub@36 {
				compatible = "mediatek,camera_sub";
				reg = <0x36>;
				status = "okay";
			};
		};

		i2c@1100a000 {
			compatible = "mediatek,mt6580-i2c", "mediatek,i2c1";
			cell-index = <0x1>;
			reg = <0x1100a000 0x1000>;
			interrupts = <0x0 0x29 0x8 0x0 0x33 0x8>;
			clock-div = <0xa>;
			#address-cells = <0x1>;
			#size-cells = <0x0>;

			cap_touch@5d {
				compatible = "mediatek,cap_touch";
				reg = <0x5d>;
				status = "okay";
			};

			ext_buck@60 {
				compatible = "mediatek,ext_buck";
				reg = <0x60>;
				status = "okay";
			};
		};

		i2c@1100b000 {
			compatible = "mediatek,mt6580-i2c", "mediatek,i2c2";
			cell-index = <0x2>;
			reg = <0x1100b000 0x1000>;
			interrupts = <0x0 0x2a 0x8 0x0 0x34 0x8>;
			clock-div = <0xa>;
			#address-cells = <0x1>;
			#size-cells = <0x0>;

			strobe_main@63 {
				compatible = "mediatek,strobe_main";
				reg = <0x63>;
				status = "okay";
			};

			msensor@2d {
				compatible = "mediatek,msensor";
				reg = <0x2d>;
				status = "okay";
			};

			gsensor@15 {
				compatible = "mediatek,gsensor";
				reg = <0x15>;
				status = "okay";
			};

			gyro@68 {
				compatible = "mediatek,gyro";
				reg = <0x68>;
				status = "okay";
			};

			alsps@48 {
				compatible = "mediatek,alsps";
				reg = <0x48>;
				status = "okay";
			};
		};

		touch@0 {
			compatible = "mediatek,mt6580-touch";
			vtouch-supply = <0xe>;
			interrupt-parent = <0xc>;
			interrupts = <0x5 0x2>;
			debounce = <0x5 0x0>;
			status = "okay";
			tpd-resolution = <0x2d0 0x500>;
			use-tpd-button = <0x1>;
			tpd-key-num = <0x3>;
			tpd-key-local = <0x8b 0xac 0x9e 0x0>;
			tpd-key-dim-local = <0xb4 0x564 0x64 0x28 0x168 0x564 0x64 0x28 0x21c 0x564 0x64 0x28 0x0 0x0 0x0 0x0>;
			tpd-max-touch-num = <0x5>;
			tpd-filter-enable = <0x1>;
			tpd-filter-pixel-density = <0x7c>;
			tpd-filter-custom-prameters = <0x0 0x0 0x0 0x0 0x0 0x0 0x0 0x0 0x0 0x0 0x0 0x0>;
			tpd-filter-custom-speed = <0x0 0x0 0x0>;
			pinctrl-names = "default", "state_eint_as_int", "state_eint_output0", "state_eint_output1", "state_rst_output0", "state_rst_output1";
			pinctrl-0 = <0xf>;
			pinctrl-1 = <0x10>;
			pinctrl-2 = <0x11>;
			pinctrl-3 = <0x12>;
			pinctrl-4 = <0x13>;
			pinctrl-5 = <0x14>;
		};

		accdet {
			compatible = "mediatek,mt6580-accdet";
			interrupt-parent = <0xc>;
			interrupts = <0x10 0x8>;
			debounce = <0x10 0x3e800>;
			status = "okay";
			accdet-mic-vol = <0x7>;
			headset-mode-setting = <0x500 0x200 0x1 0x1f0 0x800 0x800 0x20>;
			accdet-plugout-debounce = <0x14>;
			accdet-mic-mode = <0x1>;
			headset-three-key-threshold = <0x0 0x5a 0xf0 0x1f4>;
			headset-four-key-threshold = <0x0 0x3b 0x7b 0xc3 0x1c2>;
			pinctrl-names = "default", "state_eint_as_int";
			pinctrl-0 = <0x15>;
			pinctrl-1 = <0x16>;
		};

		gse_1 {
			compatible = "mediatek, gse_1-eint";
			status = "disabled";
		};

		spi@1100c000 {
			compatible = "mediatek,mt6580-spi";
			cell-index = <0x0>;
			reg = <0x1100c000 0x1000>;
			interrupts = <0x0 0x40 0x8>;
			mediatek,spi-padmacro = <0x0>;
		};

		THERM_CTRL@0x1100D000 {
			compatible = "mediatek,THERM_CTRL";
			reg = <0x1100d000 0x1000>;
			interrupts = <0x0 0x25 0x8>;
		};

		btif_tx@11000380 {
			compatible = "mediatek,btif_tx";
			reg = <0x11000380 0x80>;
			interrupts = <0x0 0x36 0x8>;
		};

		btif_rx@11000400 {
			compatible = "mediatek,btif_rx";
			reg = <0x11000400 0x80>;
			interrupts = <0x0 0x37 0x8>;
		};

		btif@1100e000 {
			compatible = "mediatek,btif";
			reg = <0x1100e000 0x1000>;
			interrupts = <0x0 0x43 0x8>;
		};

		gps {
			compatible = "mediatek,gps";
		};

		BTCVSD@0x18000000 {
			compatible = "mediatek,audio_bt_cvsd";
			offset = <0xc00 0x2 0xfd0 0xfd4 0xfd8>;
			reg = <0x10001000 0x1000 0x18000000 0x10000 0x18080000 0x8000>;
			interrupts = <0x0 0x99 0x8>;
		};

		consys@18070000 {
			compatible = "mediatek,mt6580-consys";
			reg = <0x18070000 0x200 0x10007000 0x100 0x10000000 0x2000 0x10006000 0x1000 0x10005000 0x1000>;
			interrupts = <0x0 0x9a 0x8 0x0 0x9c 0x8>;
			vcn18-supply = <0x17>;
			vcn28-supply = <0x18>;
			vcn33_bt-supply = <0x19>;
			vcn33_wifi-supply = <0x1a>;
			pinctrl-names = "default", "gps_lna_state_init", "gps_lna_state_oh", "gps_lna_state_ol";
			pinctrl-0 = <0x1b>;
			pinctrl-1 = <0x1c>;
			pinctrl-2 = <0x1d>;
			pinctrl-3 = <0x1e>;
			status = "okay";
		};

		WIFI@0x180F0000 {
			compatible = "mediatek,WIFI";
			reg = <0x180f0000 0x5c>;
			interrupts = <0x0 0x9b 0x8>;
		};

		DISP_PWM@0x1100F000 {
			compatible = "mediatek,DISP_PWM";
			reg = <0x1100f000 0x1000>;
			interrupts = <0x0 0x21 0x8>;
		};

		USB0@0x11100000 {
			compatible = "mediatek,USB0";
			cell-index = <0x0>;
			reg = <0x11100000 0x10000 0x11110000 0x10000>;
			interrupts = <0x0 0x20 0x8>;
			mode = <0x2>;
			multipoint = <0x1>;
			dyn_fifo = <0x1>;
			soft_con = <0x1>;
			dma = <0x1>;
			num_eps = <0x10>;
			dma_channels = <0x8>;
			iddig_gpio = <0x9 0x3>;
			drvvbus_gpio = <0xa 0x3>;

			usbiddig {
				compatible = "mediatek,usb_iddig_eint";
			};
		};

		ledrgb {
			compatible = "mediatek,mt6580-led-rgb";
			pinctrl-names = "default", "led_chr_0", "led_chr_1";
			pinctrl-0 = <0x1f>;
			pinctrl-1 = <0x20>;
			pinctrl-2 = <0x21>;
			status = "okay";
		};

		fingerprint {
			compatible = "mediatek,fingerprint";
			interrupt-parent = <0xc>;
			interrupts = <0xc 0x8>;
			debounce = <0xc 0x1f400>;
			status = "okay";
			pinctrl-names = "fingerprint_default", "fingerprint_pin_irq", "fingerprint_reset_high", "fingerprint_reset_low";
			pinctrl-0 = <0x22>;
			pinctrl-1 = <0x23>;
			pinctrl-2 = <0x24>;
			pinctrl-3 = <0x25>;
		};

		speaker_node {
			compatible = "mediatek,set_speaker";
			gpio_speaker = <0x4 0xe 0x0>;
		};

		hall_1 {
			compatible = "mediatek,hall";
			pinctrl-names = "default", "hall_pins_as_eint";
			pinctrl-0 = <0x26>;
			pinctrl-1 = <0x27>;
			status = "okay";
		};

		flashlight {
			compatible = "mediatek,mt6580-flashlight";
			pinctrl-names = "flash_mode_0", "flash_mode_1", "flash_en_0", "flash_en_1", "flash_1w_0", "flash_1w_1";
			pinctrl-0 = <0x28>;
			pinctrl-1 = <0x29>;
			pinctrl-2 = <0x2a>;
			pinctrl-3 = <0x2b>;
			pinctrl-4 = <0x2c>;
			pinctrl-5 = <0x2d>;
			status = "okay";
		};

		usbphy@0 {
			compatible = "usb-nop-xceiv";
		};

		audio@11140000 {
			compatible = "mediatek,audio";
			reg = <0x11140000 0x10000>;
			interrupts = <0x0 0x50 0x8>;
		};

		mt_soc_dl1_pcm@11140000 {
			compatible = "mediatek,mt_soc_pcm_dl1";
			reg = <0x11140000 0x1000>;
			interrupts = <0x0 0x50 0x8>;
			audclk-gpio = <0x1a 0x0>;
			audmiso-gpio = <0x1c 0x0>;
			audmosi-gpio = <0x1b 0x0>;
			extspkamp-gpio = <0xe 0x0>;
			extspkamp2-gpio = <0xc 0x0>;
			pinctrl-names = "default", "audpmicclk-mode0", "audpmicclk-mode1", "extamp-pulllow", "extamp-pullhigh";
			pinctrl-0 = <0x2e>;
			pinctrl-1 = <0x2f>;
			pinctrl-2 = <0x30>;
			pinctrl-3 = <0x31>;
			pinctrl-4 = <0x32>;
			status = "okay";
		};

		mt_soc_ul1_PCM@11140000 {
			compatible = "mediatek,mt_soc_pcm_capture";
		};

		mt_soc_voice_md1@11140000 {
			compatible = "mediatek,mt_soc_pcm_voice_md1";
		};

		mt_soc_hdmi_pcm@11140000 {
			compatible = "mediatek,mt_soc_pcm_hdmi";
		};

		mt_soc_uldlloopback_pcm@11140000 {
			compatible = "mediatek,mt_soc_pcm_uldlloopback";
		};

		mt_soc_i2s0_pcm@11140000 {
			compatible = "mediatek,mt_soc_pcm_dl1_i2s0";
		};

		mt_soc_mrgrx_pcm@11140000 {
			compatible = "mediatek,mt_soc_pcm_mrgrx";
		};

		mt_soc_mrgrx_awb_pcm@11140000 {
			compatible = "mediatek,mt_soc_pcm_mrgrx_awb";
		};

		mt_soc_fm_i2s_pcm@0x11140000 {
			compatible = "mediatek,mt_soc_pcm_fm_i2s";
		};

		mt_soc_fm_i2s_awb_pcm@11140000 {
			compatible = "mediatek,mt_soc_pcm_fm_i2s_awb";
		};

		mt_soc_i2s0dl1_pcm@11140000 {
			compatible = "mediatek,mt_soc_pcm_dl1_i2s0Dl1";
		};

		mt_soc_dl1_awb_pcm@11140000 {
			compatible = "mediatek,mt_soc_pcm_dl1_awb";
		};

		mt_soc_voice_md1_bt@11140000 {
			compatible = "mediatek,mt_soc_pcm_voice_md1_bt";
		};

		mt_soc_voip_bt_out@11140000 {
			compatible = "mediatek,mt_soc_pcm_dl1_bt";
		};

		mt_soc_voip_bt_in@11140000 {
			compatible = "mediatek,mt_soc_pcm_bt_dai";
		};

		mt_soc_tdmrx_pcm@11140000 {
			compatible = "mediatek,mt_soc_tdm_capture";
		};

		mt_soc_fm_mrgtx_pcm@11140000 {
			compatible = "mediatek,mt_soc_pcm_fmtx";
		};

		mt_soc_ul2_pcm@11140000 {
			compatible = "mediatek,mt_soc_pcm_capture2";
		};

		mt_soc_i2s0_awb_pcm@11140000 {
			compatible = "mediatek,mt_soc_pcm_i2s0_awb";
		};

		mt_soc_voice_md2@11140000 {
			compatible = "mediatek,mt_soc_pcm_voice_md2";
		};

		mt_soc_routing_pcm@11140000 {
			compatible = "mediatek,mt_soc_pcm_routing";
		};

		mt_soc_voice_md2_bt@11140000 {
			compatible = "mediatek,mt_soc_pcm_voice_md2_bt";
		};

		mt_soc_hp_impedance_pcm@11140000 {
			compatible = "mediatek,Mt_soc_pcm_hp_impedance";
		};

		mt_soc_codec_name@11140000 {
			compatible = "mediatek,mt_soc_codec_63xx";
		};

		mt_soc_dummy_pcm@11140000 {
			compatible = "mediatek,mt_soc_pcm_dummy";
		};

		mt_soc_codec_dummy_name@11140000 {
			compatible = "mediatek,mt_soc_codec_dummy";
		};

		mt_soc_routing_dai_name@11140000 {
			compatible = "mediatek,mt_soc_dai_routing";
		};

		mt_soc_dai_name@11140000 {
			compatible = "mediatek,mt_soc_dai_stub";
		};

		mt_soc_dl2_pcm@11140000 {
			compatible = "mediatek,mt_soc_pcm_dl2";
		};

		AHB_MOM@0x11150000 {
			compatible = "mediatek,AHB_MOM";
			reg = <0x11150000 0x10000>;
		};

		MDI@0x11160000 {
			compatible = "mediatek,MDI";
			reg = <0x11160000 0x10000>;
		};

		G3D_CONFIG@0x13000000 {
			compatible = "mediatek,G3D_CONFIG";
			reg = <0x13000000 0x1000>;
		};

		MALI@0x13010000 {
			compatible = "mediatek,MALI";
			reg = <0x13010000 0x10000>;
		};

		mmsys_config@14000000 {
			compatible = "mediatek,mmsys_config";
			reg = <0x14000000 0x1000>;
			interrupts = <0x0 0x84 0x8>;
		};

		mdp_rdma@14001000 {
			compatible = "mediatek,mdp_rdma";
			reg = <0x14001000 0x1000>;
			interrupts = <0x0 0x71 0x8>;
		};

		mdp_rsz0@14002000 {
			compatible = "mediatek,mdp_rsz0";
			reg = <0x14002000 0x1000>;
			interrupts = <0x0 0x72 0x8>;
		};

		mdp_rsz1@14003000 {
			compatible = "mediatek,mdp_rsz1";
			reg = <0x14003000 0x1000>;
			interrupts = <0x0 0x73 0x8>;
		};

		mdp_wdma@14004000 {
			compatible = "mediatek,mdp_wdma";
			reg = <0x14004000 0x1000>;
			interrupts = <0x0 0x75 0x8>;
		};

		mdp_wrot@14005000 {
			compatible = "mediatek,mdp_wrot";
			reg = <0x14005000 0x1000>;
			interrupts = <0x0 0x76 0x8>;
		};

		mdp_tdshp@14006000 {
			compatible = "mediatek,mdp_tdshp";
			reg = <0x14006000 0x1000>;
			interrupts = <0x0 0x74 0x8>;
		};

		lcm {
			compatible = "mediatek,mt6580-lcm";
		};

		nfc {
			compatible = "mediatek,nfc-gpio-v2";
			gpio-ven = <0xb>;
			gpio-rst = <0xa>;
			gpio-eint = <0xc>;
			gpio-irq = <0x9>;
		};

		DISPSYS@0x14007000 {
			compatible = "mediatek,DISPSYS";
			reg = <0x14000000 0x1000 0x14007000 0x1000 0x14008000 0x1000 0x14009000 0x1000 0x1400a000 0x1000 0x1400b000 0x1000 0x1400c000 0x1000 0x1400d000 0x1000 0x1400e000 0x1000 0x1400f000 0x1000 0x14010000 0x1000 0x14011000 0x1000 0x14012000 0x1000 0x14013000 0x1000 0x1100f000 0x1000 0x14015000 0x1000 0x14016000 0x1000 0x14017000 0x1000 0x14018000 0x1000>;
			interrupts = <0x0 0x0 0x8 0x0 0x77 0x8 0x0 0x0 0x8 0x0 0x79 0x8 0x0 0x0 0x8 0x0 0x7b 0x8 0x0 0x7c 0x8 0x0 0x0 0x8 0x0 0x7e 0x8 0x0 0x7f 0x8 0x0 0x80 0x8 0x0 0x0 0x8 0x0 0x82 0x8 0x0 0x0 0x8 0x0 0x0 0x8 0x0 0x70 0x8 0x0 0x0 0x8 0x0 0x0 0x8 0x0 0x0 0x8>;
		};

		DISP_OVL0@0x14007000 {
			compatible = "mediatek,DISP_OVL0";
			reg = <0x14007000 0x1000>;
			interrupts = <0x0 0x77 0x8>;
		};

		DISP_OVL1@0x14008000 {
			compatible = "mediatek,DISP_OVL1";
			reg = <0x14008000 0x1000>;
		};

		DISP_RDMA0@0x14009000 {
			compatible = "mediatek,DISP_RDMA0";
			reg = <0x14009000 0x1000>;
			interrupts = <0x0 0x79 0x8>;
		};

		DISP_RDMA1@0x1400A000 {
			compatible = "mediatek,DISP_RDMA1";
			reg = <0x1400a000 0x1000>;
		};

		DISP_WDMA@0x1400B000 {
			compatible = "mediatek,DISP_WDMA";
			reg = <0x1400b000 0x1000>;
			interrupts = <0x0 0x7b 0x8>;
		};

		DISP_COLOR@0x1400C000 {
			compatible = "mediatek,DISP_COLOR";
			reg = <0x1400c000 0x1000>;
			interrupts = <0x0 0x7c 0x8>;
		};

		DISP_CCORR@0x1400D000 {
			compatible = "mediatek,DISP_CCORR";
			reg = <0x1400d000 0x1000>;
		};

		DISP_AAL@0x1400E000 {
			compatible = "mediatek,DISP_AAL";
			reg = <0x1400e000 0x1000>;
			interrupts = <0x0 0x7e 0x8>;
		};

		DISP_GAMMA@0x1400F000 {
			compatible = "mediatek,DISP_GAMMA";
			reg = <0x1400f000 0x1000>;
			interrupts = <0x0 0x7f 0x8>;
		};

		DISP_DITHER@0x14010000 {
			compatible = "mediatek,DISP_DITHER";
			reg = <0x14010000 0x1000>;
			interrupts = <0x0 0x80 0x8>;
		};

		DISP_UFOE@0x14011000 {
			compatible = "mediatek,DISP_UFOE";
			reg = <0x14011000 0x1000>;
		};

		DSI@0x14012000 {
			compatible = "mediatek,DSI";
			reg = <0x14012000 0x1000>;
		};

		DPI@0x14013000 {
			compatible = "mediatek,DPI";
			reg = <0x14013000 0x1000>;
		};

		PTP_FSM@0x1100D000 {
			compatible = "mediatek,PTP_FSM";
			reg = <0x1100d000 0x1000>;
			interrupts = <0x0 0x2b 0x8>;
		};

		MM_MUTEX@0x14015000 {
			compatible = "mediatek,MM_MUTEX";
			reg = <0x14015000 0x1000>;
			interrupts = <0x0 0x70 0x8>;
		};

		SMI_LARB0@0x14016000 {
			compatible = "mediatek,SMI_LARB0";
			reg = <0x14016000 0x1000>;
			interrupts = <0x0 0x85 0x8>;
		};

		SMI_COMMON@0x14017000 {
			compatible = "mediatek,SMI_COMMON";
			reg = <0x14017000 0x1000 0x14016000 0x1000 0x15001000 0x1000>;
		};

		MIPI_TX_CONFIG@0x14018000 {
			compatible = "mediatek,MIPI_TX_CONFIG";
			reg = <0x14018000 0x1000>;
		};

		ISPSYS@0x15000000 {
			compatible = "mediatek,ISPSYS";
			reg = <0x15004000 0x9000 0x15000000 0x10000 0x10011000 0x4000 0x10017000 0x1000>;
			interrupts = <0x0 0x8e 0x8 0x0 0x8b 0x8>;
		};

		ISP_SYSR@0x15000000 {
			compatible = "mediatek,ISP_SYSR";
		};

		ISP_PIPEM@0x15000000 {
			compatible = "mediatek,ISP_PIPEM";
		};

		kd_camera_hw1@15008000 {
			compatible = "mediatek,camera_hw";
			reg = <0x15008000 0x1000>;
			vcama-supply = <0x33>;
			vcamd-supply = <0x34>;
			vcamaf-supply = <0x35>;
			vcamio-supply = <0x36>;
			vcamd_main2-supply = <0x34>;
			vcamd_sub-supply = <0x34>;
			vcamio_main2-supply = <0x36>;
			vcamio_sub-supply = <0x36>;
			vcama_main2-supply = <0x33>;
			vcama_sub-supply = <0x33>;
			status = "okay";
			pinctrl-names = "default", "cam0_rst0", "cam0_rst1", "cam0_pnd0", "cam0_pnd1", "cam1_rst0", "cam1_rst1", "cam1_pnd0", "cam1_pnd1", "cam_ldo0_0", "cam_ldo0_1", "cam1_gpio_serial", "cam1_gpio_mipi", "cam_mclk1_enable", "cam_mclk1_disable", "cam_mclk2_enable", "cam_mclk2_disable", "lens_af_en_0", "lens_af_en_1";
			pinctrl-0 = <0x37>;
			pinctrl-1 = <0x38>;
			pinctrl-2 = <0x39>;
			pinctrl-3 = <0x3a>;
			pinctrl-4 = <0x3b>;
			pinctrl-5 = <0x3c>;
			pinctrl-6 = <0x3d>;
			pinctrl-7 = <0x3e>;
			pinctrl-8 = <0x3f>;
			pinctrl-9 = <0x40>;
			pinctrl-10 = <0x41>;
			pinctrl-11 = <0x42>;
			pinctrl-12 = <0x43>;
			pinctrl-13 = <0x44>;
			pinctrl-14 = <0x45>;
			pinctrl-15 = <0x46>;
			pinctrl-16 = <0x47>;
			pinctrl-17 = <0x48>;
			pinctrl-18 = <0x49>;
		};

		kd_camera_hw2@15008000 {
			compatible = "mediatek,camera_hw2";
			reg = <0x15008000 0x1000>;
		};

		seninf_top@15008000 {
			compatible = "mediatek,SENINF_TOP";
			reg = <0x15008000 0x1000>;
			interrupts = <0x0 0x8e 0x8>;
		};

		CAM_0@0x15004000 {
			compatible = "mediatek,CAM_0";
			reg = <0x15004000 0x1000>;
			interrupts = <0x0 0x8b 0x8>;
		};

		CAM_1@0x15005000 {
			compatible = "mediatek,CAM_1";
			reg = <0x15005000 0x1000>;
		};

		VENC@0x15009000 {
			compatible = "mediatek,VENC";
			reg = <0x15009000 0x1000>;
			interrupts = <0x0 0x8a 0x8>;
		};

		VDEC@0x1500B000 {
			compatible = "mediatek,VDEC";
			reg = <0x1500b000 0x1000>;
			interrupts = <0x0 0x89 0x8>;
		};

		SMI_LARB1@0x15001000 {
			compatible = "mediatek,SMI_LARB1";
			reg = <0x15001000 0x1000>;
			interrupts = <0x0 0x88 0x8>;
		};

		IMGSYS_CONFIG@0x15000000 {
			compatible = "mediatek,IMGSYS_CONFIG";
			reg = <0x15000000 0x1000>;
		};

		hwmsensor@0 {
			compatible = "mediatek,hwmsensor";
		};

		gsensor@0 {
			compatible = "mediatek,gsensor";
		};

		als_ps@0 {
			compatible = "mediatek,als_ps";
			pinctrl-names = "pin_default", "pin_cfg";
			pinctrl-0 = <0x4a>;
			pinctrl-1 = <0x4b>;
			status = "okay";
		};

		m_acc_pl@0 {
			compatible = "mediatek,m_acc_pl";
		};

		m_alsps_pl@0 {
			compatible = "mediatek,m_alsps_pl";
		};

		sensorHub@0 {
			compatible = "mediatek,sensorHub";
		};

		shf@0 {
			compatible = "mediatek,shf";
		};

		m_batch_pl@0 {
			compatible = "mediatek,m_batch_pl";
		};

		gyroscope@0 {
			compatible = "mediatek,gyroscope";
			pinctrl-names = "pin_default", "pin_cfg";
			pinctrl-0 = <0x4c>;
			pinctrl-1 = <0x4d>;
			status = "okay";
		};

		m_gyro_pl@0 {
			compatible = "mediatek,m_gyro_pl";
		};

		barometer@0 {
			compatible = "mediatek,barometer";
		};

		m_baro_pl@0 {
			compatible = "mediatek,m_baro_pl";
		};

		msensor@0 {
			compatible = "mediatek,msensor";
		};

		m_mag_pl@0 {
			compatible = "mediatek,m_mag_pl";
		};

		orientation@0 {
			compatible = "mediatek,orientation";
		};

		pedometer@0 {
			compatible = "mediatek,pedometer";
		};

		m_pdr_pl@0 {
			compatible = "mediatek,m_pdr_pl";
		};

		step_counter@0 {
			compatible = "mediatek,step_counter";
		};

		m_step_c_pl@0 {
			compatible = "mediatek,m_step_c_pl";
		};

		in_pocket@0 {
			compatible = "mediatek,in_pocket";
		};

		m_inpk_pl@0 {
			compatible = "mediatek,m_inpk_pl";
		};

		shake@0 {
			compatible = "mediatek,shake";
		};

		m_shk_pl@0 {
			compatible = "mediatek,m_shk_pl";
		};

		face_down@0 {
			compatible = "mediatek,face_down";
		};

		m_fdn_pl@0 {
			compatible = "mediatek,m_fdn_pl";
		};

		activity@0 {
			compatible = "mediatek,activity";
		};

		m_act_pl@0 {
			compatible = "mediatek,m_act_pl";
		};

		heart_rate@0 {
			compatible = "mediatek,heart_rate";
		};

		m_hrm_pl@0 {
			compatible = "mediatek,m_hrm_pl";
		};

		tilt_detector@0 {
			compatible = "mediatek,tilt_detector";
		};

		m_tilt_pl@0 {
			compatible = "mediatek,m_tilt_pl";
		};

		wake_gesture@0 {
			compatible = "mediatek,wake_gesture";
		};

		m_wag_pl@0 {
			compatible = "mediatek,m_wag_pl";
		};

		glance_gesture@0 {
			compatible = "mediatek,glance_gesture";
		};

		m_glg_pl@0 {
			compatible = "mediatek,m_glg_pl";
		};

		pick_up@0 {
			compatible = "mediatek,pick_up";
		};

		m_pkup_pl@0 {
			compatible = "mediatek,m_pkup_pl";
		};

		als {
			compatible = "mediatek, als-eint";
			interrupt-parent = <0xc>;
			interrupts = <0x6 0x8>;
			debounce = <0x6 0x0>;
			status = "okay";
		};

		mtkfb@0 {
			compatible = "mediatek,mtkfb";
			pinctrl-names = "default", "mode_te_gpio", "mode_te_te", "lcm_rst_out0_gpio", "lcm_rst_out1_gpio", "pwm_test_pin_mux_gpio66";
			pinctrl-0 = <0x1b>;
			pinctrl-1 = <0x4e>;
			pinctrl-2 = <0x4f>;
			pinctrl-3 = <0x50>;
			pinctrl-4 = <0x51>;
			pinctrl-5 = <0x52>;
			status = "okay";
		};

		dsi_te {
			compatible = "mediatek, dsi_te-eint";
		};
	};

	MOBICORE {
		compatible = "trustonic,mobicore";
		interrupts = <0x0 0x97 0x1>;
	};

	mt_pmic_regulator {
		compatible = "mediatek,mt_pmic";

		buck_regulators {
			compatible = "mediatek,mt_pmic_buck_regulators";

			buck_vpa {
				regulator-name = "vpa";
				regulator-min-microvolt = <0x7a120>;
				regulator-max-microvolt = <0x37b1d0>;
				regulator-ramp-delay = <0xc350>;
				regulator-enable-ramp-delay = <0xb4>;
			};

			buck_vproc {
				regulator-name = "vproc";
				regulator-min-microvolt = <0xaae60>;
				regulator-max-microvolt = <0x16caf6>;
				regulator-ramp-delay = <0x186a>;
				regulator-enable-ramp-delay = <0xb4>;
				regulator-always-on;
				regulator-boot-on;
			};
		};

		ldo_regulators {
			compatible = "mediatek,mt_pmic_ldo_regulators";

			ldo_vcn28 {
				regulator-name = "vcn28";
				regulator-min-microvolt = <0x1b7740>;
				regulator-max-microvolt = <0x2ab980>;
				regulator-enable-ramp-delay = <0x108>;
				regulator-default-on = <0x0>;
				status = "okay";
				linux,phandle = <0x18>;
				phandle = <0x18>;
			};

			ldo_vtcxo {
				regulator-name = "vtcxo";
				regulator-min-microvolt = <0x2191c0>;
				regulator-max-microvolt = <0x2191c0>;
				regulator-enable-ramp-delay = <0x6e>;
				linux,phandle = <0x53>;
				phandle = <0x53>;
			};

			ldo_va {
				regulator-name = "va";
				regulator-min-microvolt = <0x1b7740>;
				regulator-max-microvolt = <0x2625a0>;
				regulator-enable-ramp-delay = <0x6e>;
				linux,phandle = <0x54>;
				phandle = <0x54>;
			};

			ldo_vcama {
				regulator-name = "vcama";
				regulator-min-microvolt = <0x16e360>;
				regulator-max-microvolt = <0x2ab980>;
				regulator-enable-ramp-delay = <0x108>;
				regulator-default-on = <0x0>;
				status = "okay";
				linux,phandle = <0x33>;
				phandle = <0x33>;
			};

			ldo_vcn33_bt {
				regulator-name = "vcn33_bt";
				regulator-min-microvolt = <0x325aa0>;
				regulator-max-microvolt = <0x36ee80>;
				regulator-enable-ramp-delay = <0x108>;
				linux,phandle = <0x19>;
				phandle = <0x19>;
			};

			ldo_vcn33_wifi {
				regulator-name = "vcn33_wifi";
				regulator-min-microvolt = <0x325aa0>;
				regulator-max-microvolt = <0x36ee80>;
				regulator-enable-ramp-delay = <0x108>;
				linux,phandle = <0x1a>;
				phandle = <0x1a>;
			};

			ldo_vio28 {
				regulator-name = "vio28";
				regulator-min-microvolt = <0x2ab980>;
				regulator-max-microvolt = <0x2ab980>;
				regulator-enable-ramp-delay = <0x108>;
				regulator-boot-on;
				linux,phandle = <0x55>;
				phandle = <0x55>;
			};

			ldo_vsim1 {
				regulator-name = "vsim1";
				regulator-min-microvolt = <0x1b7740>;
				regulator-max-microvolt = <0x2dc6c0>;
				regulator-enable-ramp-delay = <0x108>;
				regulator-default-on = <0x0>;
				status = "okay";
				linux,phandle = <0x56>;
				phandle = <0x56>;
			};

			ldo_vsim2 {
				regulator-name = "vsim2";
				regulator-min-microvolt = <0x1b7740>;
				regulator-max-microvolt = <0x2dc6c0>;
				regulator-enable-ramp-delay = <0x108>;
				regulator-default-on = <0x0>;
				status = "okay";
				linux,phandle = <0x57>;
				phandle = <0x57>;
			};

			ldo_vusb {
				regulator-name = "vusb";
				regulator-min-microvolt = <0x325aa0>;
				regulator-max-microvolt = <0x325aa0>;
				regulator-enable-ramp-delay = <0x108>;
				regulator-boot-on;
				linux,phandle = <0x58>;
				phandle = <0x58>;
			};

			ldo_vgp1 {
				regulator-name = "vgp1";
				regulator-min-microvolt = <0x124f80>;
				regulator-max-microvolt = <0x325aa0>;
				regulator-enable-ramp-delay = <0x108>;
				regulator-default-on = <0x0>;
				status = "okay";
				linux,phandle = <0xe>;
				phandle = <0xe>;
			};

			ldo_vgp2 {
				regulator-name = "vgp2";
				regulator-min-microvolt = <0x124f80>;
				regulator-max-microvolt = <0x2dc6c0>;
				regulator-enable-ramp-delay = <0x108>;
				regulator-default-on = <0x0>;
				status = "okay";
				linux,phandle = <0x59>;
				phandle = <0x59>;
			};

			ldo_vemc_3v3 {
				regulator-name = "vemc_3v3";
				regulator-min-microvolt = <0x2dc6c0>;
				regulator-max-microvolt = <0x325aa0>;
				regulator-enable-ramp-delay = <0x108>;
				regulator-boot-on;
				regulator-default-on = <0x0>;
				status = "okay";
				linux,phandle = <0x5a>;
				phandle = <0x5a>;
			};

			ldo_vcamaf {
				regulator-name = "vcamaf";
				regulator-min-microvolt = <0x124f80>;
				regulator-max-microvolt = <0x325aa0>;
				regulator-enable-ramp-delay = <0x108>;
				regulator-default-on = <0x0>;
				status = "okay";
				linux,phandle = <0x35>;
				phandle = <0x35>;
			};

			ldo_vmc {
				regulator-name = "vmc";
				regulator-min-microvolt = <0x1b7740>;
				regulator-max-microvolt = <0x325aa0>;
				regulator-enable-ramp-delay = <0x2c>;
				regulator-boot-on;
				regulator-default-on = <0x0>;
				status = "okay";
				linux,phandle = <0x5b>;
				phandle = <0x5b>;
			};

			ldo_vmch {
				regulator-name = "vmch";
				regulator-min-microvolt = <0x2dc6c0>;
				regulator-max-microvolt = <0x325aa0>;
				regulator-enable-ramp-delay = <0x2c>;
				regulator-default-on = <0x0>;
				status = "okay";
				linux,phandle = <0x5c>;
				phandle = <0x5c>;
			};

			ldo_vibr {
				regulator-name = "vibr";
				regulator-min-microvolt = <0x124f80>;
				regulator-max-microvolt = <0x325aa0>;
				regulator-enable-ramp-delay = <0x2c>;
				regulator-default-on = <0x0>;
				status = "okay";
				linux,phandle = <0x5d>;
				phandle = <0x5d>;
			};

			ldo_vrtc {
				regulator-name = "vrtc";
				regulator-min-microvolt = <0x2ab980>;
				regulator-max-microvolt = <0x2ab980>;
				regulator-enable-ramp-delay = <0x2c>;
				linux,phandle = <0x5e>;
				phandle = <0x5e>;
			};

			ldo_vm {
				regulator-name = "vm";
				regulator-min-microvolt = <0x124f80>;
				regulator-max-microvolt = <0x1b7740>;
				regulator-enable-ramp-delay = <0x108>;
				regulator-boot-on;
				regulator-default-on = <0x0>;
				status = "okay";
				linux,phandle = <0x5f>;
				phandle = <0x5f>;
			};

			ldo_vrf18 {
				regulator-name = "vrf18";
				regulator-min-microvolt = <0x1b7740>;
				regulator-max-microvolt = <0x1b7740>;
				regulator-enable-ramp-delay = <0xdc>;
				regulator-default-on = <0x0>;
				status = "okay";
				linux,phandle = <0x60>;
				phandle = <0x60>;
			};

			ldo_vio18 {
				regulator-name = "vio18";
				regulator-min-microvolt = <0x1b7740>;
				regulator-max-microvolt = <0x1b7740>;
				regulator-enable-ramp-delay = <0x108>;
				regulator-boot-on;
				linux,phandle = <0x61>;
				phandle = <0x61>;
			};

			ldo_vcamd {
				regulator-name = "vcamd";
				regulator-min-microvolt = <0x124f80>;
				regulator-max-microvolt = <0x1b7740>;
				regulator-enable-ramp-delay = <0x108>;
				regulator-default-on = <0x0>;
				status = "okay";
				linux,phandle = <0x34>;
				phandle = <0x34>;
			};

			ldo_vcamio {
				regulator-name = "vcamio";
				regulator-min-microvolt = <0x1b7740>;
				regulator-max-microvolt = <0x1b7740>;
				regulator-enable-ramp-delay = <0xdc>;
				linux,phandle = <0x62>;
				phandle = <0x62>;
			};

			ldo_vgp3 {
				regulator-name = "vgp3";
				regulator-min-microvolt = <0x124f80>;
				regulator-max-microvolt = <0x1b7740>;
				regulator-enable-ramp-delay = <0x108>;
				regulator-default-on = <0x0>;
				status = "okay";
				linux,phandle = <0x63>;
				phandle = <0x63>;
			};

			ldo_vcn_1v8 {
				regulator-name = "vcn_1v8";
				regulator-min-microvolt = <0x1b7740>;
				regulator-max-microvolt = <0x1b7740>;
				regulator-enable-ramp-delay = <0x2c>;
				regulator-default-on = <0x0>;
				status = "okay";
				linux,phandle = <0x17>;
				phandle = <0x17>;
			};

			vcanio_ldo_reg {
				regulator-name = "vcanio";
				regulator-default-on = <0x0>;
				status = "okay";
				linux,phandle = <0x36>;
				phandle = <0x36>;
			};

			vcn33_ldo_reg {
				regulator-name = "vcn33";
				regulator-default-on = <0x0>;
				status = "okay";
			};
		};

		regulators_supply {
			compatible = "mediatek,mt_pmic_regulator_supply";
			vcn28-supply = <0x18>;
			vtcxo-supply = <0x53>;
			va-supply = <0x54>;
			vcn33_bt-supply = <0x19>;
			vcn33_wifi-supply = <0x1a>;
			vio28-supply = <0x55>;
			vsim1-supply = <0x56>;
			vsim2-supply = <0x57>;
			vusb-supply = <0x58>;
			vgp1-supply = <0xe>;
			vgp2-supply = <0x59>;
			vemc_3v3-supply = <0x5a>;
			vcamaf-supply = <0x35>;
			vmc-supply = <0x5b>;
			vmch-supply = <0x5c>;
			vibr-supply = <0x5d>;
			vrtc-supply = <0x5e>;
			vm-supply = <0x5f>;
			vrf18-supply = <0x60>;
			vio18-supply = <0x61>;
			vcamd-supply = <0x34>;
			vcamio-supply = <0x62>;
			vgp3-supply = <0x63>;
			vcn_1v8-supply = <0x17>;
		};
	};

	rf_clock_buffer {
		compatible = "mediatek,rf_clock_buffer";
		#mediatek,clkbuf-quantity = <0x4>;
		#mediatek,clkbuf-config = <0x2 0x1 0x1 0x1>;
		mediatek,clkbuf-quantity = <0x4>;
		mediatek,clkbuf-config = <0x2 0x2 0x1 0x1>;
		status = "okay";
	};

	trusty {
		compatible = "android,trusty-smc-v1";
		ranges;
		#address-cells = <0x2>;
		#size-cells = <0x2>;

		irq {
			compatible = "android,trusty-irq-v1";
			ppi-interrupt-parent = <0x1>;
		};

		log {
			compatible = "android,trusty-log-v1";
		};

		virtio {
			compatible = "android,trusty-virtio-v1";
		};

		mtee {
			compatible = "mediatek,trusty-mtee-v1";
		};
	};

	led@0 {
		compatible = "mediatek,red";
		led_mode = <0x0>;
		data = <0x1>;
		pwm_config = <0x0 0x0 0x0 0x0 0x0>;
	};

	led@1 {
		compatible = "mediatek,green";
		led_mode = <0x0>;
		data = <0x1>;
		pwm_config = <0x0 0x0 0x0 0x0 0x0>;
	};

	led@2 {
		compatible = "mediatek,blue";
		led_mode = <0x0>;
		data = <0x1>;
		pwm_config = <0x0 0x0 0x0 0x0 0x0>;
	};

	led@3 {
		compatible = "mediatek,jogball-backlight";
		led_mode = <0x0>;
		data = <0x1>;
		pwm_config = <0x0 0x0 0x0 0x0 0x0>;
	};

	led@4 {
		compatible = "mediatek,keyboard-backlight";
		led_mode = <0x0>;
		data = <0x1>;
		pwm_config = <0x0 0x0 0x0 0x0 0x0>;
	};

	led@5 {
		compatible = "mediatek,button-backlight";
		led_mode = <0x0>;
		data = <0x1>;
		pwm_config = <0x0 0x0 0x0 0x0 0x0>;
	};

	led@6 {
		compatible = "mediatek,lcd-backlight";
		led_mode = <0x5>;
		data = <0x1>;
		pwm_config = <0x0 0x0 0x0 0x0 0x0>;
	};

	vibrator@0 {
		compatible = "mediatek,vibrator";
		vib_timer = <0x19>;
		vib_limit = <0x9>;
		vib_vol = <0x6>;
	};

	cust_accel@0 {
		compatible = "mediatek,mxc400x";
		i2c_num = <0x2>;
		i2c_addr = <0x15 0x0 0x0 0x0>;
		direction = <0x5>;
		power_id = <0xffff>;
		power_vol = <0x0>;
		firlen = <0x0>;
		is_batch_supported = <0x0>;
	};

	cust_alsps@0 {
		compatible = "mediatek,stk3x1x";
		i2c_num = <0x2>;
		i2c_addr = <0x90 0x0 0x0 0x0>;
		polling_mode_ps = <0x0>;
		polling_mode_als = <0x1>;
		power_id = <0xffff>;
		power_vol = <0x0>;
		als_level = <0x5 0x9 0x24 0x3b 0x52 0x84 0xcd 0x111 0x1f4 0x34d 0x470 0x609 0x93c 0x122f 0x1b46>;
		als_value = <0x0 0xa 0x28 0x41 0x5a 0x91 0xe1 0x12c 0x226 0x3a2 0x4e2 0x6a4 0xa28 0x1400 0x1e00 0x2800>;
		ps_threshold_high = <0x96>;
		ps_threshold_low = <0x64>;
		state_val = <0x0>;
		psctrl_val = <0x31>;
		alsctrl_val = <0x38>;
		ledctrl_val = <0xff>;
		wait_val = <0x7>;
		stk_max_min_diff = <0x96>;
		stk_lt_n_ct = <0x32>;
		stk_ht_n_ct = <0x64>;
	};

	cust_mag@0 {
		compatible = "mediatek,qmcX983";
		i2c_num = <0x2>;
		i2c_addr = <0x2d 0x0 0x0 0x0>;
		direction = <0x4>;
		power_id = <0xffff>;
		power_vol = <0x0>;
		is_batch_supported = <0x0>;
	};

	cust_gyro@0 {
		compatible = "mediatek,ITG1010";
		i2c_num = <0x2>;
		i2c_addr = <0x68 0x0 0x0 0x0>;
		direction = <0x1>;
		power_id = <0xffff>;
		power_vol = <0x0>;
		firlen = <0x0>;
		is_batch_supported = <0x0>;
	};

	hall@0 {
		compatible = "mediatek,ah1883";
		hall_gpio_num = <0x7>;
	};

	mt-extmem@0 {
		compatible = "mediatek,mt-extmem";
	};
};
